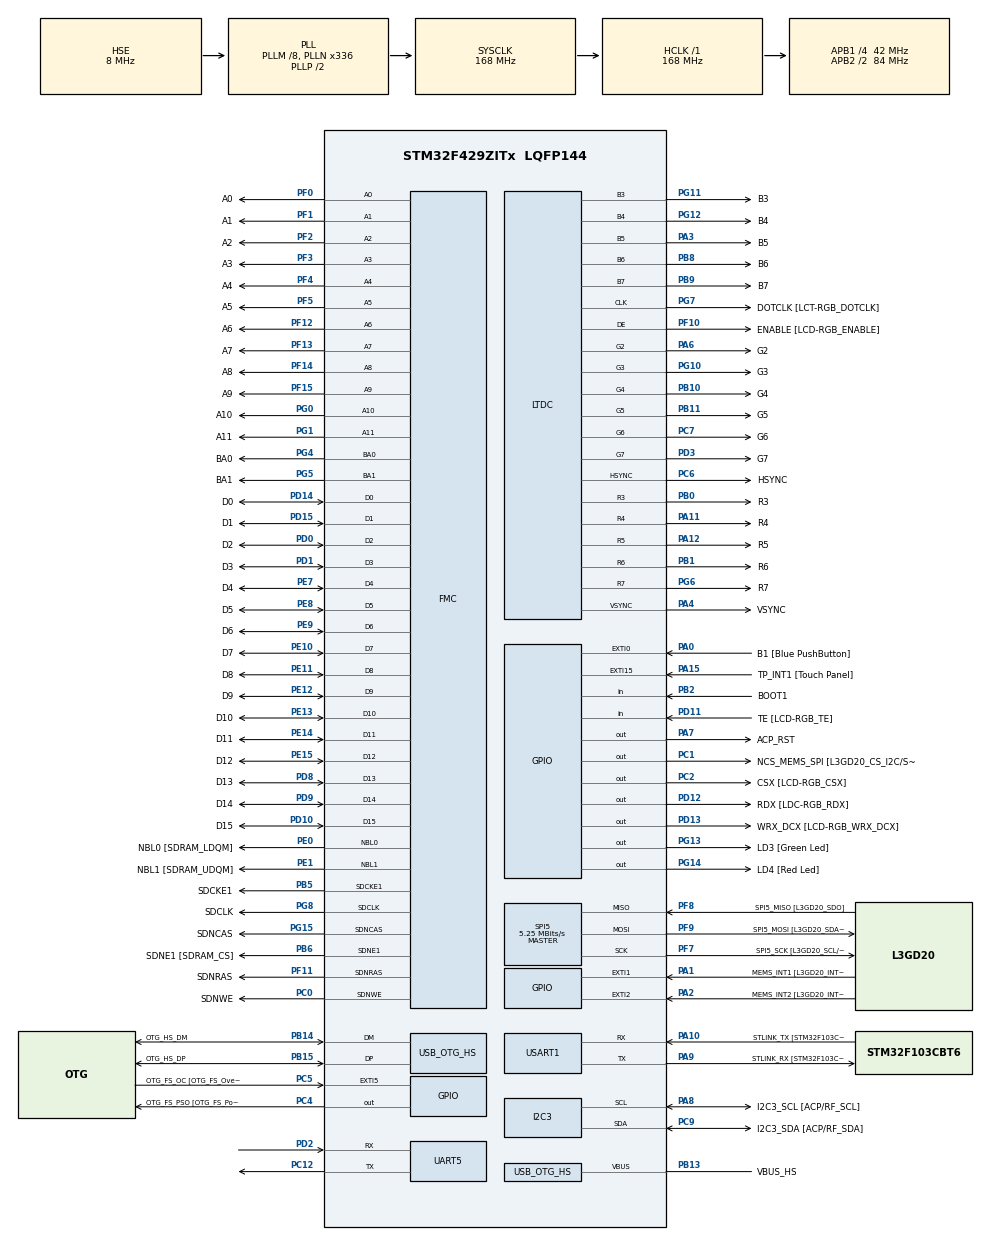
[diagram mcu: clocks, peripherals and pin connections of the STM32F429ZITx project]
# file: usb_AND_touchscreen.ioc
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FMC.CASLatency1=FMC_SDRAM_CAS_LATENCY_3
FMC.ExitSelfRefreshDelay1=7
FMC.LoadToActiveDelay1=2
FMC.RCDDelay1=2
FMC.RPDelay1=2
FMC.RPDelay2=2
FMC.ReadBurst1=FMC_SDRAM_RBURST_DISABLE
FMC.ReadPipeDelay1=FMC_SDRAM_RPIPE_DELAY_1
FMC.ReadPipeDelay2=FMC_SDRAM_RPIPE_DELAY_1
FMC.RowCycleDelay1=7
FMC.RowCycleDelay2=7
FMC.SDClockPeriod1=FMC_SDRAM_CLOCK_PERIOD_2
FMC.SDClockPeriod2=FMC_SDRAM_CLOCK_PERIOD_2
FMC.SelfRefreshTime1=4
FMC.WriteRecoveryTime1=3
LTDC.ActiveH=320
LTDC.ActiveW=240
LTDC.Alpha_L0=255
LTDC.BlendingFactor1_L0=LTDC_BLENDING_FACTOR1_PAxCA
LTDC.BlendingFactor2_L0=LTDC_BLENDING_FACTOR2_PAxCA
LTDC.FBStartAdress_L0=0xD0000000
LTDC.HBP=20
LTDC.HFP=10
LTDC.HSync=10
LTDC.ImageHeight_L0=320
LTDC.ImageWidth_L0=240
LTDC.Layers=0
LTDC.PixelFormat_L0=LTDC_PIXEL_FORMAT_RGB565
LTDC.VFP=4
LTDC.VSync=2
LTDC.WindowX1_L0=240
LTDC.WindowY1_L0=320
Mcu.Family=STM32F4
Mcu.Name=STM32F429ZITx
Mcu.Package=LQFP144
NVIC.DMA2D_IRQn=true\:5\:0\:true\:false\:true\:true\:true\:true
NVIC.LTDC_IRQn=true\:5\:0\:true\:false\:true\:true\:true\:true
NVIC.OTG_HS_IRQn=true\:0\:0\:false\:false\:true\:true\:true\:true
NVIC.PriorityGroup=NVIC_PRIORITYGROUP_4
NVIC.TIM1_UP_TIM10_IRQn=true\:0\:0\:false\:false\:true\:true\:true\:true
NVIC.TIM6_DAC_IRQn=true\:15\:0\:false\:false\:true\:false\:true\:true
NVIC.TimeBase=TIM6_DAC_IRQn
NVIC.TimeBaseIP=TIM6
PA0/WKUP.GPIO_Label=B1 [Blue PushButton]
PA0/WKUP.GPIO_ModeDefaultEXTI=GPIO_MODE_EVT_RISING
PA0/WKUP.GPIO_PuPd=GPIO_NOPULL
PA0/WKUP.Signal=GPXTI0
PA1.GPIO_Label=MEMS_INT1 [L3GD20_INT1]
PA1.GPIO_ModeDefaultEXTI=GPIO_MODE_EVT_RISING
PA1.GPIO_PuPd=GPIO_NOPULL
PA1.Signal=GPXTI1
PA10.GPIO_Label=STLINK_TX [STM32F103CBT6_PA2]
PA10.Mode=Asynchronous
PA10.Signal=USART1_RX
PA11.GPIO_Label=R4
PA11.GPIO_Mode=GPIO_MODE_AF_PP
PA11.GPIO_PuPd=GPIO_NOPULL
PA11.GPIO_Speed=GPIO_SPEED_FREQ_LOW
PA11.Mode=RGB565
PA11.Signal=LTDC_R4
PA12.GPIO_Label=R5
PA12.GPIO_Mode=GPIO_MODE_AF_PP
PA12.GPIO_PuPd=GPIO_NOPULL
PA12.GPIO_Speed=GPIO_SPEED_FREQ_LOW
PA12.Mode=RGB565
PA12.Signal=LTDC_R5
PA13.GPIO_Label=SWDIO
PA13.Mode=Serial_Wire
PA13.Signal=SYS_JTMS-SWDIO
PA14.GPIO_Label=SWCLK
PA14.Mode=Serial_Wire
PA14.Signal=SYS_JTCK-SWCLK
PA15.GPIO_Label=TP_INT1 [Touch Panel]
PA15.GPIO_ModeDefaultEXTI=GPIO_MODE_EVT_RISING
PA15.GPIO_PuPd=GPIO_NOPULL
PA15.Signal=GPXTI15
PA2.GPIO_Label=MEMS_INT2 [L3GD20_INT2]
PA2.GPIO_ModeDefaultEXTI=GPIO_MODE_EVT_RISING
PA2.GPIO_PuPd=GPIO_NOPULL
PA2.Signal=GPXTI2
PA3.GPIO_Label=B5
PA3.GPIO_Mode=GPIO_MODE_AF_PP
PA3.GPIO_PuPd=GPIO_NOPULL
PA3.GPIO_Speed=GPIO_SPEED_FREQ_LOW
PA3.Mode=RGB565
PA3.Signal=LTDC_B5
PA4.GPIO_Label=VSYNC
PA4.GPIO_Mode=GPIO_MODE_AF_PP
PA4.GPIO_PuPd=GPIO_NOPULL
PA4.GPIO_Speed=GPIO_SPEED_FREQ_LOW
PA4.Mode=RGB565
PA4.Signal=LTDC_VSYNC
PA6.GPIO_Label=G2
PA6.GPIO_Mode=GPIO_MODE_AF_PP
PA6.GPIO_PuPd=GPIO_NOPULL
PA6.GPIO_Speed=GPIO_SPEED_FREQ_LOW
PA6.Mode=RGB565
PA6.Signal=LTDC_G2
PA7.GPIO_Label=ACP_RST
PA7.GPIO_Mode=GPIO_MODE_OUTPUT_PP
PA7.GPIO_PuPd=GPIO_NOPULL
PA7.GPIO_Speed=GPIO_SPEED_FREQ_LOW
PA7.Signal=GPIO_Output
PA8.GPIO_Label=I2C3_SCL [ACP/RF_SCL]
PA8.GPIO_Mode=GPIO_MODE_AF_OD
PA8.GPIO_Pu=GPIO_PULLUP
PA8.GPIO_PuPd=GPIO_NOPULL
PA8.GPIO_Speed=GPIO_SPEED_FREQ_LOW
PA8.Mode=I2C
PA8.Signal=I2C3_SCL
PA9.GPIO_Label=STLINK_RX [STM32F103CBT6_PA3]
PA9.Mode=Asynchronous
PA9.Signal=USART1_TX
PB0.GPIO_Label=R3
PB0.GPIO_Mode=GPIO_MODE_AF_PP
PB0.GPIO_PuPd=GPIO_NOPULL
PB0.GPIO_Speed=GPIO_SPEED_FREQ_LOW
PB0.Mode=RGB565
PB0.Signal=LTDC_R3
PB1.GPIO_Label=R6
PB1.GPIO_Mode=GPIO_MODE_AF_PP
PB1.GPIO_PuPd=GPIO_NOPULL
PB1.GPIO_Speed=GPIO_SPEED_FREQ_LOW
PB1.Mode=RGB565
PB1.Signal=LTDC_R6
PB10.GPIO_Label=G4
PB10.GPIO_Mode=GPIO_MODE_AF_PP
PB10.GPIO_PuPd=GPIO_NOPULL
PB10.GPIO_Speed=GPIO_SPEED_FREQ_LOW
PB10.Mode=RGB565
PB10.Signal=LTDC_G4
PB11.GPIO_Label=G5
PB11.GPIO_Mode=GPIO_MODE_AF_PP
PB11.GPIO_PuPd=GPIO_NOPULL
PB11.GPIO_Speed=GPIO_SPEED_FREQ_LOW
PB11.Mode=RGB565
PB11.Signal=LTDC_G5
PB12.GPIO_Label=OTG_HS_ID
PB12.GPIO_Mode=GPIO_MODE_AF_PP
PB12.GPIO_PuPd=GPIO_NOPULL
PB12.GPIO_Speed=GPIO_SPEED_FREQ_LOW
PB12.Signal=USB_OTG_HS_ID
PB13.GPIO_Label=VBUS_HS
PB13.GPIO_Mode=GPIO_MODE_INPUT
PB13.GPIO_PuPd=GPIO_NOPULL
PB13.Mode=Activate_VBUS_FS
PB13.Signal=USB_OTG_HS_VBUS
PB14.GPIO_Label=OTG_HS_DM
PB14.GPIO_Mode=GPIO_MODE_AF_PP
PB14.GPIO_PuPd=GPIO_NOPULL
PB14.GPIO_Speed=GPIO_SPEED_FREQ_LOW
PB14.Mode=Host_FS
PB14.Signal=USB_OTG_HS_DM
PB15.GPIO_Label=OTG_HS_DP
PB15.GPIO_Mode=GPIO_MODE_AF_PP
PB15.GPIO_PuPd=GPIO_NOPULL
PB15.GPIO_Speed=GPIO_SPEED_FREQ_LOW
PB15.Mode=Host_FS
PB15.Signal=USB_OTG_HS_DP
PB2/BOOT1.GPIO_Label=BOOT1
PB2/BOOT1.GPIO_Mode=GPIO_MODE_INPUT
PB2/BOOT1.GPIO_PuPd=GPIO_NOPULL
PB2/BOOT1.Signal=GPIO_Input
PB5.GPIO_Label=SDCKE1
PB5.GPIO_Mode=GPIO_MODE_AF_PP
PB5.GPIO_PuPd=GPIO_NOPULL
PB5.GPIO_Speed=GPIO_SPEED_FREQ_VERY_HIGH
PB5.Mode=SdramChipSelect2_1
PB5.Signal=FMC_SDCKE1
PB6.GPIO_Label=SDNE1 [SDRAM_CS]
PB6.GPIO_Mode=GPIO_MODE_AF_PP
PB6.GPIO_PuPd=GPIO_NOPULL
PB6.GPIO_Speed=GPIO_SPEED_FREQ_VERY_HIGH
PB6.Mode=SdramChipSelect2_1
PB6.Signal=FMC_SDNE1
PB8.GPIO_Label=B6
PB8.GPIO_Mode=GPIO_MODE_AF_PP
PB8.GPIO_PuPd=GPIO_NOPULL
PB8.GPIO_Speed=GPIO_SPEED_FREQ_LOW
PB8.Mode=RGB565
PB8.Signal=LTDC_B6
PB9.GPIO_Label=B7
PB9.GPIO_Mode=GPIO_MODE_AF_PP
PB9.GPIO_PuPd=GPIO_NOPULL
PB9.GPIO_Speed=GPIO_SPEED_FREQ_LOW
PB9.Mode=RGB565
PB9.Signal=LTDC_B7
PC0.GPIO_Label=SDNWE
PC0.GPIO_Mode=GPIO_MODE_AF_PP
PC0.GPIO_PuPd=GPIO_NOPULL
PC0.GPIO_Speed=GPIO_SPEED_FREQ_VERY_HIGH
PC0.Signal=FMC_SDNWE
PC1.GPIO_Label=NCS_MEMS_SPI [L3GD20_CS_I2C/SPI]
PC1.GPIO_Mode=GPIO_MODE_OUTPUT_PP
PC1.GPIO_PuPd=GPIO_NOPULL
PC1.GPIO_Speed=GPIO_SPEED_FREQ_LOW
PC1.Signal=GPIO_Output
PC10.GPIO_Label=R2
PC10.GPIO_Mode=GPIO_MODE_AF_PP
PC10.GPIO_PuPd=GPIO_NOPULL
PC10.GPIO_Speed=GPIO_SPEED_FREQ_LOW
PC10.Signal=LTDC_R2
PC12.Mode=Asynchronous
PC12.Signal=UART5_TX
PC14/OSC32_IN.GPIO_Label=PC14-OSC32_IN
PC14/OSC32_IN.Signal=RCC_OSC32_IN
PC15/OSC32_OUT.GPIO_Label=PC15-OSC32_OUT
PC15/OSC32_OUT.Signal=RCC_OSC32_OUT
PC2.GPIO_Label=CSX [LCD-RGB_CSX]
PC2.GPIO_Mode=GPIO_MODE_OUTPUT_PP
PC2.GPIO_PuPd=GPIO_NOPULL
PC2.GPIO_Speed=GPIO_SPEED_FREQ_LOW
PC2.Signal=GPIO_Output
PC4.GPIO_Label=OTG_FS_PSO [OTG_FS_PowerSwitchOn]
PC4.GPIO_Mode=GPIO_MODE_OUTPUT_PP
PC4.GPIO_PuPd=GPIO_NOPULL
PC4.GPIO_Speed=GPIO_SPEED_FREQ_LOW
PC4.Signal=GPIO_Output
PC5.GPIO_Label=OTG_FS_OC [OTG_FS_OverCurrent]
PC5.GPIO_ModeDefaultEXTI=GPIO_MODE_EVT_RISING
PC5.Signal=GPXTI5
PC6.GPIO_Label=HSYNC
PC6.GPIO_Mode=GPIO_MODE_AF_PP
PC6.GPIO_PuPd=GPIO_NOPULL
PC6.GPIO_Speed=GPIO_SPEED_FREQ_LOW
PC6.Mode=RGB565
PC6.Signal=LTDC_HSYNC
PC7.GPIO_Label=G6
PC7.GPIO_Mode=GPIO_MODE_AF_PP
PC7.GPIO_PuPd=GPIO_NOPULL
PC7.GPIO_Speed=GPIO_SPEED_FREQ_LOW
PC7.Mode=RGB565
PC7.Signal=LTDC_G6
PC9.GPIO_Label=I2C3_SDA [ACP/RF_SDA]
PC9.GPIO_Mode=GPIO_MODE_AF_OD
PC9.GPIO_Pu=GPIO_PULLUP
PC9.GPIO_PuPd=GPIO_NOPULL
PC9.GPIO_Speed=GPIO_SPEED_FREQ_LOW
PC9.Mode=I2C
PC9.Signal=I2C3_SDA
PD0.GPIO_Label=D2
PD0.GPIO_Mode=GPIO_MODE_AF_PP
PD0.GPIO_PuPd=GPIO_NOPULL
PD0.GPIO_Speed=GPIO_SPEED_FREQ_VERY_HIGH
PD0.Signal=FMC_D2_DA2
PD1.GPIO_Label=D3
PD1.GPIO_Mode=GPIO_MODE_AF_PP
PD1.GPIO_PuPd=GPIO_NOPULL
PD1.GPIO_Speed=GPIO_SPEED_FREQ_VERY_HIGH
PD1.Signal=FMC_D3_DA3
PD10.GPIO_Label=D15
PD10.GPIO_Mode=GPIO_MODE_AF_PP
PD10.GPIO_PuPd=GPIO_NOPULL
PD10.GPIO_Speed=GPIO_SPEED_FREQ_VERY_HIGH
PD10.Signal=FMC_D15_DA15
PD11.GPIO_Label=TE [LCD-RGB_TE]
PD11.GPIO_Mode=GPIO_MODE_INPUT
PD11.GPIO_PuPd=GPIO_NOPULL
PD11.Signal=GPIO_Input
PD12.GPIO_Label=RDX [LDC-RGB_RDX]
PD12.GPIO_Mode=GPIO_MODE_OUTPUT_PP
PD12.GPIO_PuPd=GPIO_NOPULL
PD12.GPIO_Speed=GPIO_SPEED_FREQ_LOW
PD12.Signal=GPIO_Output
PD13.GPIO_Label=WRX_DCX [LCD-RGB_WRX_DCX]
PD13.GPIO_Mode=GPIO_MODE_OUTPUT_PP
PD13.GPIO_PuPd=GPIO_NOPULL
PD13.GPIO_Speed=GPIO_SPEED_FREQ_LOW
PD13.Signal=GPIO_Output
PD14.GPIO_Label=D0
PD14.GPIO_Mode=GPIO_MODE_AF_PP
PD14.GPIO_PuPd=GPIO_NOPULL
PD14.GPIO_Speed=GPIO_SPEED_FREQ_VERY_HIGH
PD14.Signal=FMC_D0_DA0
PD15.GPIO_Label=D1
PD15.GPIO_Mode=GPIO_MODE_AF_PP
PD15.GPIO_PuPd=GPIO_NOPULL
PD15.GPIO_Speed=GPIO_SPEED_FREQ_VERY_HIGH
PD15.Signal=FMC_D1_DA1
PD2.Mode=Asynchronous
PD2.Signal=UART5_RX
PD3.GPIO_Label=G7
PD3.GPIO_Mode=GPIO_MODE_AF_PP
PD3.GPIO_PuPd=GPIO_NOPULL
PD3.GPIO_Speed=GPIO_SPEED_FREQ_LOW
PD3.Mode=RGB565
PD3.Signal=LTDC_G7
PD5.Signal=USART2_TX
PD6.GPIO_Label=B2
PD6.GPIO_Mode=GPIO_MODE_AF_PP
PD6.GPIO_PuPd=GPIO_NOPULL
PD6.GPIO_Speed=GPIO_SPEED_FREQ_LOW
PD6.Signal=LTDC_B2
PD8.GPIO_Label=D13
PD8.GPIO_Mode=GPIO_MODE_AF_PP
PD8.GPIO_PuPd=GPIO_NOPULL
PD8.GPIO_Speed=GPIO_SPEED_FREQ_VERY_HIGH
PD8.Signal=FMC_D13_DA13
PD9.GPIO_Label=D14
PD9.GPIO_Mode=GPIO_MODE_AF_PP
PD9.GPIO_PuPd=GPIO_NOPULL
PD9.GPIO_Speed=GPIO_SPEED_FREQ_VERY_HIGH
PD9.Signal=FMC_D14_DA14
PE0.GPIO_Label=NBL0 [SDRAM_LDQM]
PE0.GPIO_Mode=GPIO_MODE_AF_PP
PE0.GPIO_PuPd=GPIO_NOPULL
PE0.GPIO_Speed=GPIO_SPEED_FREQ_VERY_HIGH
PE0.Signal=FMC_NBL0
PE1.GPIO_Label=NBL1 [SDRAM_UDQM]
PE1.GPIO_Mode=GPIO_MODE_AF_PP
PE1.GPIO_PuPd=GPIO_NOPULL
PE1.GPIO_Speed=GPIO_SPEED_FREQ_VERY_HIGH
PE1.Signal=FMC_NBL1
PE10.GPIO_Label=D7
PE10.GPIO_Mode=GPIO_MODE_AF_PP
PE10.GPIO_PuPd=GPIO_NOPULL
PE10.GPIO_Speed=GPIO_SPEED_FREQ_VERY_HIGH
PE10.Signal=FMC_D7_DA7
PE11.GPIO_Label=D8
PE11.GPIO_Mode=GPIO_MODE_AF_PP
PE11.GPIO_PuPd=GPIO_NOPULL
PE11.GPIO_Speed=GPIO_SPEED_FREQ_VERY_HIGH
PE11.Signal=FMC_D8_DA8
PE12.GPIO_Label=D9
PE12.GPIO_Mode=GPIO_MODE_AF_PP
PE12.GPIO_PuPd=GPIO_NOPULL
PE12.GPIO_Speed=GPIO_SPEED_FREQ_VERY_HIGH
PE12.Signal=FMC_D9_DA9
PE13.GPIO_Label=D10
PE13.GPIO_Mode=GPIO_MODE_AF_PP
PE13.GPIO_PuPd=GPIO_NOPULL
PE13.GPIO_Speed=GPIO_SPEED_FREQ_VERY_HIGH
PE13.Signal=FMC_D10_DA10
PE14.GPIO_Label=D11
PE14.GPIO_Mode=GPIO_MODE_AF_PP
PE14.GPIO_PuPd=GPIO_NOPULL
PE14.GPIO_Speed=GPIO_SPEED_FREQ_VERY_HIGH
PE14.Signal=FMC_D11_DA11
PE15.GPIO_Label=D12
PE15.GPIO_Mode=GPIO_MODE_AF_PP
PE15.GPIO_PuPd=GPIO_NOPULL
PE15.GPIO_Speed=GPIO_SPEED_FREQ_VERY_HIGH
PE15.Signal=FMC_D12_DA12
PE7.GPIO_Label=D4
PE7.GPIO_Mode=GPIO_MODE_AF_PP
PE7.GPIO_PuPd=GPIO_NOPULL
PE7.GPIO_Speed=GPIO_SPEED_FREQ_VERY_HIGH
PE7.Signal=FMC_D4_DA4
PE8.GPIO_Label=D5
PE8.GPIO_Mode=GPIO_MODE_AF_PP
PE8.GPIO_PuPd=GPIO_NOPULL
PE8.GPIO_Speed=GPIO_SPEED_FREQ_VERY_HIGH
PE8.Signal=FMC_D5_DA5
PE9.GPIO_Label=D6
PE9.GPIO_Mode=GPIO_MODE_AF_PP
PE9.GPIO_PuPd=GPIO_NOPULL
PE9.GPIO_Speed=GPIO_SPEED_FREQ_VERY_HIGH
PE9.Signal=FMC_D6_DA6
PF0.GPIO_Label=A0
PF0.GPIO_Mode=GPIO_MODE_AF_PP
PF0.GPIO_PuPd=GPIO_NOPULL
PF0.GPIO_Speed=GPIO_SPEED_FREQ_VERY_HIGH
PF0.Signal=FMC_A0
PF1.GPIO_Label=A1
PF1.GPIO_Mode=GPIO_MODE_AF_PP
PF1.GPIO_PuPd=GPIO_NOPULL
PF1.GPIO_Speed=GPIO_SPEED_FREQ_VERY_HIGH
PF1.Signal=FMC_A1
PF10.GPIO_Label=ENABLE [LCD-RGB_ENABLE]
PF10.GPIO_Mode=GPIO_MODE_AF_PP
PF10.GPIO_PuPd=GPIO_NOPULL
PF10.GPIO_Speed=GPIO_SPEED_FREQ_LOW
PF10.Mode=RGB565
PF10.Signal=LTDC_DE
PF11.GPIO_Label=SDNRAS
PF11.GPIO_Mode=GPIO_MODE_AF_PP
PF11.GPIO_PuPd=GPIO_NOPULL
PF11.GPIO_Speed=GPIO_SPEED_FREQ_VERY_HIGH
PF11.Signal=FMC_SDNRAS
PF12.GPIO_Label=A6
PF12.GPIO_Mode=GPIO_MODE_AF_PP
PF12.GPIO_PuPd=GPIO_NOPULL
PF12.GPIO_Speed=GPIO_SPEED_FREQ_VERY_HIGH
PF12.Signal=FMC_A6
PF13.GPIO_Label=A7
PF13.GPIO_Mode=GPIO_MODE_AF_PP
PF13.GPIO_PuPd=GPIO_NOPULL
PF13.GPIO_Speed=GPIO_SPEED_FREQ_VERY_HIGH
PF13.Signal=FMC_A7
PF14.GPIO_Label=A8
PF14.GPIO_Mode=GPIO_MODE_AF_PP
PF14.GPIO_PuPd=GPIO_NOPULL
PF14.GPIO_Speed=GPIO_SPEED_FREQ_VERY_HIGH
PF14.Signal=FMC_A8
PF15.GPIO_Label=A9
PF15.GPIO_Mode=GPIO_MODE_AF_PP
PF15.GPIO_PuPd=GPIO_NOPULL
PF15.GPIO_Speed=GPIO_SPEED_FREQ_VERY_HIGH
PF15.Signal=FMC_A9
PF2.GPIO_Label=A2
PF2.GPIO_Mode=GPIO_MODE_AF_PP
PF2.GPIO_PuPd=GPIO_NOPULL
PF2.GPIO_Speed=GPIO_SPEED_FREQ_VERY_HIGH
PF2.Signal=FMC_A2
PF3.GPIO_Label=A3
PF3.GPIO_Mode=GPIO_MODE_AF_PP
PF3.GPIO_PuPd=GPIO_NOPULL
PF3.GPIO_Speed=GPIO_SPEED_FREQ_VERY_HIGH
PF3.Signal=FMC_A3
PF4.GPIO_Label=A4
PF4.GPIO_Mode=GPIO_MODE_AF_PP
PF4.GPIO_PuPd=GPIO_NOPULL
PF4.GPIO_Speed=GPIO_SPEED_FREQ_VERY_HIGH
PF4.Signal=FMC_A4
PF5.GPIO_Label=A5
PF5.GPIO_Mode=GPIO_MODE_AF_PP
PF5.GPIO_PuPd=GPIO_NOPULL
PF5.GPIO_Speed=GPIO_SPEED_FREQ_VERY_HIGH
PF5.Signal=FMC_A5
PF7.GPIO_Label=SPI5_SCK [L3GD20_SCL/SPC]
PF7.GPIO_Mode=GPIO_MODE_AF_PP
PF7.GPIO_PuPd=GPIO_NOPULL
PF7.GPIO_Speed=GPIO_SPEED_FREQ_LOW
PF7.Mode=Full_Duplex_Master
PF7.Signal=SPI5_SCK
PF8.GPIO_Label=SPI5_MISO [L3GD20_SDO]
PF8.GPIO_Mode=GPIO_MODE_AF_PP
PF8.GPIO_PuPd=GPIO_NOPULL
PF8.GPIO_Speed=GPIO_SPEED_FREQ_LOW
PF8.Mode=Full_Duplex_Master
PF8.Signal=SPI5_MISO
PF9.GPIO_Label=SPI5_MOSI [L3GD20_SDA/SDI/SDO]
PF9.GPIO_Mode=GPIO_MODE_AF_PP
PF9.GPIO_PuPd=GPIO_NOPULL
PF9.GPIO_Speed=GPIO_SPEED_FREQ_LOW
PF9.Mode=Full_Duplex_Master
PF9.Signal=SPI5_MOSI
PG0.GPIO_Label=A10
PG0.GPIO_Mode=GPIO_MODE_AF_PP
PG0.GPIO_PuPd=GPIO_NOPULL
PG0.GPIO_Speed=GPIO_SPEED_FREQ_VERY_HIGH
PG0.Signal=FMC_A10
PG1.GPIO_Label=A11
PG1.GPIO_Mode=GPIO_MODE_AF_PP
PG1.GPIO_PuPd=GPIO_NOPULL
PG1.GPIO_Speed=GPIO_SPEED_FREQ_VERY_HIGH
PG1.Signal=FMC_A11
PG10.GPIO_Label=G3
PG10.GPIO_Mode=GPIO_MODE_AF_PP
PG10.GPIO_PuPd=GPIO_NOPULL
PG10.GPIO_Speed=GPIO_SPEED_FREQ_LOW
PG10.Mode=RGB565
PG10.Signal=LTDC_G3
PG11.GPIO_Label=B3
PG11.GPIO_Mode=GPIO_MODE_AF_PP
PG11.GPIO_PuPd=GPIO_NOPULL
PG11.GPIO_Speed=GPIO_SPEED_FREQ_LOW
PG11.Mode=RGB565
PG11.Signal=LTDC_B3
PG12.GPIO_Label=B4
PG12.GPIO_Mode=GPIO_MODE_AF_PP
PG12.GPIO_PuPd=GPIO_NOPULL
PG12.GPIO_Speed=GPIO_SPEED_FREQ_LOW
PG12.Mode=RGB565
PG12.Signal=LTDC_B4
PG13.GPIO_Label=LD3 [Green Led]
PG13.GPIO_Mode=GPIO_MODE_OUTPUT_PP
PG13.GPIO_PuPd=GPIO_NOPULL
PG13.GPIO_Speed=GPIO_SPEED_FREQ_LOW
PG13.Signal=GPIO_Output
PG14.GPIO_Label=LD4 [Red Led]
PG14.GPIO_Mode=GPIO_MODE_OUTPUT_PP
PG14.GPIO_PuPd=GPIO_NOPULL
PG14.GPIO_Speed=GPIO_SPEED_FREQ_LOW
PG14.Signal=GPIO_Output
PG15.GPIO_Label=SDNCAS
PG15.GPIO_Mode=GPIO_MODE_AF_PP
PG15.GPIO_PuPd=GPIO_NOPULL
PG15.GPIO_Speed=GPIO_SPEED_FREQ_VERY_HIGH
PG15.Signal=FMC_SDNCAS
PG4.GPIO_Label=BA0
PG4.GPIO_Mode=GPIO_MODE_AF_PP
PG4.GPIO_PuPd=GPIO_NOPULL
PG4.GPIO_Speed=GPIO_SPEED_FREQ_VERY_HIGH
PG4.Signal=FMC_A14_BA0
PG5.GPIO_Label=BA1
PG5.GPIO_Mode=GPIO_MODE_AF_PP
PG5.GPIO_PuPd=GPIO_NOPULL
PG5.GPIO_Speed=GPIO_SPEED_FREQ_VERY_HIGH
PG5.Signal=FMC_A15_BA1
PG6.GPIO_Label=R7
PG6.GPIO_Mode=GPIO_MODE_AF_PP
PG6.GPIO_PuPd=GPIO_NOPULL
PG6.GPIO_Speed=GPIO_SPEED_FREQ_LOW
PG6.Mode=RGB565
PG6.Signal=LTDC_R7
PG7.GPIO_Label=DOTCLK [LCT-RGB_DOTCLK]
PG7.GPIO_Mode=GPIO_MODE_AF_PP
PG7.GPIO_PuPd=GPIO_NOPULL
PG7.GPIO_Speed=GPIO_SPEED_FREQ_LOW
PG7.Mode=RGB565
PG7.Signal=LTDC_CLK
PG8.GPIO_Label=SDCLK
PG8.GPIO_Mode=GPIO_MODE_AF_PP
PG8.GPIO_PuPd=GPIO_NOPULL
PG8.GPIO_Speed=GPIO_SPEED_FREQ_VERY_HIGH
PG8.Signal=FMC_SDCLK
PH0/OSC_IN.GPIO_Label=PH0-OSC_IN
PH0/OSC_IN.Mode=HSE-External-Oscillator
PH0/OSC_IN.Signal=RCC_OSC_IN
PH1/OSC_OUT.GPIO_Label=PH1-OSC_OUT
PH1/OSC_OUT.Mode=HSE-External-Oscillator
PH1/OSC_OUT.Signal=RCC_OSC_OUT
ProjectManager.HeapSize=0x200
ProjectManager.StackSize=0x400
ProjectManager.TargetToolchain=STM32CubeIDE
RCC.48MHZClocksFreq_Value=48000000
RCC.AHBFreq_Value=168000000
RCC.APB1CLKDivider=RCC_HCLK_DIV4
RCC.APB1Freq_Value=42000000
RCC.APB1TimFreq_Value=84000000
RCC.APB2CLKDivider=RCC_HCLK_DIV2
RCC.APB2Freq_Value=84000000
RCC.APB2TimFreq_Value=168000000
RCC.CortexFreq_Value=168000000
RCC.FLatency-AdvancedSettings=FLASH_LATENCY_5
RCC.HCLKFreq_Value=168000000
RCC.HSE_VALUE=8000000
RCC.HSI_VALUE=16000000
RCC.LSE_VALUE=32768
RCC.PLLM=8
RCC.PLLN=336
RCC.PLLQ=7
RCC.PLLSAIDivR=RCC_PLLSAIDIVR_8
RCC.PLLSAIN=192
RCC.PLLSAIR=4
RCC.SYSCLKFreq_VALUE=168000000
RCC.SYSCLKSource=RCC_SYSCLKSOURCE_PLLCLK
RCC.VCOOutputFreq_Value=336000000
SH.FMC_A0.0=FMC_A0,12b-sda1
SH.FMC_A1.0=FMC_A1,12b-sda1
SH.FMC_A10.0=FMC_A10,12b-sda1
SH.FMC_A11.0=FMC_A11,12b-sda1
SH.FMC_A14_BA0.0=FMC_BA0,FourSdramBanks1
SH.FMC_A15_BA1.0=FMC_BA1,FourSdramBanks1
SH.FMC_A2.0=FMC_A2,12b-sda1
SH.FMC_A3.0=FMC_A3,12b-sda1
SH.FMC_A4.0=FMC_A4,12b-sda1
SH.FMC_A5.0=FMC_A5,12b-sda1
SH.FMC_A6.0=FMC_A6,12b-sda1
SH.FMC_A7.0=FMC_A7,12b-sda1
SH.FMC_A8.0=FMC_A8,12b-sda1
SH.FMC_A9.0=FMC_A9,12b-sda1
SH.FMC_D0_DA0.0=FMC_D0,sd-16b-d1
SH.FMC_D10_DA10.0=FMC_D10,sd-16b-d1
SH.FMC_D11_DA11.0=FMC_D11,sd-16b-d1
SH.FMC_D12_DA12.0=FMC_D12,sd-16b-d1
SH.FMC_D13_DA13.0=FMC_D13,sd-16b-d1
SH.FMC_D14_DA14.0=FMC_D14,sd-16b-d1
SH.FMC_D15_DA15.0=FMC_D15,sd-16b-d1
SH.FMC_D1_DA1.0=FMC_D1,sd-16b-d1
SH.FMC_D2_DA2.0=FMC_D2,sd-16b-d1
SH.FMC_D3_DA3.0=FMC_D3,sd-16b-d1
SH.FMC_D4_DA4.0=FMC_D4,sd-16b-d1
SH.FMC_D5_DA5.0=FMC_D5,sd-16b-d1
SH.FMC_D6_DA6.0=FMC_D6,sd-16b-d1
SH.FMC_D7_DA7.0=FMC_D7,sd-16b-d1
SH.FMC_D8_DA8.0=FMC_D8,sd-16b-d1
SH.FMC_D9_DA9.0=FMC_D9,sd-16b-d1
SH.FMC_NBL0.0=FMC_NBL0,Sd2ByteEnable1
SH.FMC_NBL1.0=FMC_NBL1,Sd2ByteEnable1
SH.FMC_SDCLK.0=FMC_SDCLK,12b-sda1
SH.FMC_SDNCAS.0=FMC_SDNCAS,12b-sda1
SH.FMC_SDNRAS.0=FMC_SDNRAS,12b-sda1
SH.FMC_SDNWE.0=FMC_SDNWE,12b-sda1
SPI5.BaudRatePrescaler=SPI_BAUDRATEPRESCALER_16
SPI5.CalculateBaudRate=5.25 MBits/s
SPI5.Direction=SPI_DIRECTION_2LINES
SPI5.Mode=SPI_MODE_MASTER
SPI5.VirtualType=VM_MASTER
TIM1.Prescaler=167
TIM10.AutoReloadPreload=TIM_AUTORELOAD_PRELOAD_ENABLE
TIM10.Period=10000
TIM10.Prescaler=1680-1
UART5.VirtualMode=Asynchronous
USART1.VirtualMode=VM_ASYNC
USB_HOST.BSP.number=1
USB_HOST.USBH_DEBUG_LEVEL-HID_HS=3
USB_HOST.USBH_HandleTypeDef-HID_HS=hUsbHostHS
USB_HOST.USBH_MAX_DATA_BUFFER-HID_HS=3000
USB_HOST.VirtualModeHS=Hid
USB_HOST0.BSP.STBoard=false
USB_HOST0.BSP.api=UnknownBspDriver
USB_HOST0.BSP.instance=PC4
USB_HOST0.BSP.ip=GPIO
USB_HOST0.BSP.mode=Output
USB_HOST0.BSP.name=Drive_VBUS_HS
USB_HOST0.BSP.solution=PC4
USB_OTG_HS.VirtualMode-Host_FS=Host_FS
VP_CRC_VS_CRC.Mode=CRC_Activate
VP_DMA2D_VS_DMA2D.Mode=DMA2D_Activate
VP_SYS_VS_tim6.Mode=TIM6
VP_TIM10_VS_ClockSourceINT.Mode=Enable_Timer
VP_TIM1_VS_ClockSourceINT.Mode=Internal
VP_USB_HOST_VS_USB_HOST_HID_HS.Mode=HID_HS
board=STM32F429I-DISC1

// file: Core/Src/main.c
/* USER CODE BEGIN Header */
/**
 ******************************************************************************
 * @file           : main.c
 * @brief          : Main program body
 ******************************************************************************
 * @attention
 *
 * Copyright (c) 2025 STMicroelectronics.
 * All rights reserved.
 *
 * This software is licensed under terms that can be found in the LICENSE file
 * in the root directory of this software component.
 * If no LICENSE file comes with this software, it is provided AS-IS.
 *
 ******************************************************************************
 */

/****** THIS IS THE PROGRAM FLOW SO YOU DON'T GET C *********/
/* Library includes
 * Definitions of macros
 * Setting up touchscreen variables
 * stm32 prewritten function definitions
 * private function definitions
 * QR scanner USB HID host user call back function event handling
 * Main initialization code: storing test protocols for debugging
 * Initialize hardware
 * Main loop calls the touch handler with interrupt and USB is handled by STM32
 * stm32 prewritten function implementations
 * flash memory functions come first
 * touchscreen functions after
 * lastly, interrupt handler
 */

/* USER CODE END Header */
#include "main.h"
#include "usb_host.h"

/* USER CODE BEGIN Includes */
#include "usbh_hid.h"
#include <string.h>
#include "stm32f429i_discovery_lcd.h"
#include "stm32f429i_discovery_ts.h"
/* USER CODE END Includes */

/* USER CODE BEGIN PD */
#define NULL_CHAR 0
#define SOH 1
#define NEWLINE_CHAR 10   //the '/r' in python is detected as a newline (10).
#define CARRIAGE_CHAR 13  //the '\n' is just ignored
#define TAB 9
#define TRASH 0xFF

/******** Flash Memory ********/
#define SECTOR_5      ((uint32_t)0x08020000) /* Base @ of Sector 5, 128 Kbytes */
#define SECTOR_6      ((uint32_t)0x08040000) /* Base @ of Sector 6, 128 Kbytes */
#define SECTOR_7      ((uint32_t)0x08060000) /* Base @ of Sector 7, 128 Kbytes */
#define SECTOR_8      ((uint32_t)0x08080000) /* Base @ of Sector 8, 128 Kbytes */
#define SECTOR_9      ((uint32_t)0x080A0000) /* Base @ of Sector 9, 128 Kbytes */
#define SECTOR_10     ((uint32_t)0x080C0000) /* Base @ of Sector 10, 128 Kbytes */
#define SECTOR_11     ((uint32_t)0x080E0000) /* Base @ of Sector 11, 128 Kbytes */
#define SECTOR_17     ((uint32_t)0x08120000) /* Base @ of Sector 5, 128 Kbytes */
#define SECTOR_18     ((uint32_t)0x08140000) /* Base @ of Sector 6, 128 Kbytes */
#define SECTOR_19     ((uint32_t)0x08160000) /* Base @ of Sector 7, 128 Kbytes */
#define SECTOR_20     ((uint32_t)0x08180000) /* Base @ of Sector 8, 128 Kbytes  */
#define SECTOR_21     ((uint32_t)0x081A0000) /* Base @ of Sector 9, 128 Kbytes  */
#define SECTOR_22     ((uint32_t)0x081C0000) /* Base @ of Sector 10, 128 Kbytes */
#define SECTOR_23     ((uint32_t)0x081E0000) /* Base @ of Sector 11, 128 Kbytes */

// Address where you want to store your data in flash
#define NUMBER_OF_SECTORS 14
#define MAX_PROTOCOLS_IN_SECTOR 3
#define PROTOCOL_SIZE 3000
#define MAX_LINES 100
#define MAX_LINE_LENGTH 32 //for linear movement it wont be more than 32 chars
#define MAX_TITLE_SIZE 12  //you can 10 chars, but also we need newline and null

/******** LCD DISPLAY ********/
#define BUTTON_WIDTH 160
#define BUTTON_HEIGHT 40
#define NUM_BUTTONS 3
#define Y_OFFSET 20
#define SCREEN_DELAY 50
#define MAX_QUEUE_SIZE 10

/* USER CODE END PD */

CRC_HandleTypeDef hcrc;

DMA2D_HandleTypeDef hdma2d;

I2C_HandleTypeDef hi2c3;

LTDC_HandleTypeDef hltdc;

SPI_HandleTypeDef hspi5;

TIM_HandleTypeDef htim1;
TIM_HandleTypeDef htim10;

UART_HandleTypeDef huart5;
UART_HandleTypeDef huart1;

SDRAM_HandleTypeDef hsdram1;

/* USER CODE BEGIN PV */
TS_StateTypeDef TS_State;           //store touchscreen state info here
static int count = 0;               //count for interrupt
static uint8_t checkTouchFlag = 0;  //interrupt flag for main loop

typedef enum {
	PAGE_MAIN, PAGE_SELECT, PAGE_QUEUE, PAGE_CONFIRMATION, PAGE_FINISH
} PageState;
PageState currentPage = PAGE_MAIN;

typedef enum {
	EMPTY = 0, NOT_EMPTY = 1
} ButtonStatus;

typedef struct {
	uint16_t x, y, w, h;
	char label[MAX_LINE_LENGTH];
	ButtonStatus status;
} Button;

Button buttons[NUM_BUTTONS] = { { 40, 50, BUTTON_WIDTH, BUTTON_HEIGHT,
		"Protocol 1", EMPTY }, { 40, 110, BUTTON_WIDTH, BUTTON_HEIGHT,
		"Protocol 2", EMPTY }, { 40, 170, BUTTON_WIDTH, BUTTON_HEIGHT,
		"Protocol 3", EMPTY } };

Button queueButton = { 10, 270, 80, 30, "Queue" }; //x, y, w, h, label
Button backButton = { 10, 270, 80, 30, "Back" }; //x, y, w, h, label
Button nextButton = { 150, 270, 80, 30, "Next" };
Button runButton = { 150, 270, 80, 30, "Run" };
Button confirmButton = { 70, 160, 120, 40, "Confirm" };
Button queueSelectButton = { 70, 60, 100, 40, "Queue" }; //x, y, w, h, label
Button selectButton = { 70, 120, 100, 40, "Run" };
Button deleteButton = { 70, 180, 100, 40, "Delete" };

/* USER CODE END PV */

void SystemClock_Config(void);
static void MX_GPIO_Init(void);
static void MX_CRC_Init(void);
static void MX_DMA2D_Init(void);
static void MX_FMC_Init(void);
static void MX_I2C3_Init(void);
static void MX_LTDC_Init(void);
static void MX_SPI5_Init(void);
static void MX_TIM1_Init(void);
static void MX_USART1_UART_Init(void);
static void MX_TIM10_Init(void);
static void MX_UART5_Init(void);
void MX_USB_HOST_Process(void);

/* USER CODE BEGIN PFP */
void output_protocol(char line[MAX_LINES][MAX_LINE_LENGTH], int lines);

/****TOUCHSCREEN PRIVATE FUNCTIONS*******/
void erase_sector(uint32_t Sector);
void write_to_flash(const char *data, uint32_t flash_address);
uint8_t read_from_flash(char *output, uint32_t flash_address);
uint8_t storeProtocol(char gcode_file[MAX_LINES][MAX_LINE_LENGTH],
		uint32_t sector);
uint32_t sector_mapping(uint32_t sector);
uint8_t get_num_protocols_in_sector(uint32_t sector);
uint8_t get_num_lines_in_protocol(char protocol[MAX_LINES][MAX_LINE_LENGTH]);
uint8_t getFreeSector(void);
void transmitProtocol(uint32_t sector, uint32_t offset);
void queueProtocol(uint32_t sector, uint32_t offset);
void transmitQueuedProtocols(uint8_t queueSize);
uint32_t get_sector_address(uint32_t sector);
void write_number_to_flash(uint32_t flash_address, uint32_t number);
void DrawQueuePage(uint8_t queueSize);
void Touch_Init(void);
uint8_t HandleTouch(void);
void DrawMainPage(uint8_t page_num);
void DrawInfoPage(char protocolTitle[MAX_LINE_LENGTH]);
void DrawConfirmationPage(uint32_t sector, uint32_t offset);

/* USER CODE END PFP */

/* USER CODE BEGIN 0 */
/********** QR SCANNER HANDLED THROUGH USB CALL BACK FUNCTION *********/
int i = 0;
int j = 0;
static char queueBuffer[MAX_QUEUE_SIZE][MAX_LINES][MAX_LINE_LENGTH];
static uint8_t queueSize = 0;
static uint8_t pageNum = 1;
static uint8_t USB_BUSY = 0;
char qr_code_data[MAX_LINES][MAX_LINE_LENGTH] = { { '\0' } }; //static initializes strings with all null characters
HID_KEYBD_Info_TypeDef *Keyboard_Info;

/***DORJEE YOU HAVE TO CHANGE USBH_HID.H WHEN YOU GENERATE CODE****/
void USBH_HID_EventCallback(USBH_HandleTypeDef *phost) { //2.6s for 54 lines
	Keyboard_Info = USBH_HID_GetKeybdInfo(phost);
	char key = USBH_HID_GetASCIICode(Keyboard_Info);
	//disable the touchscreen interrupt functionality when usb transmission starts
	//after tab it calls itself one more time, so disable after i=0
	if (i == 1) {
		USB_BUSY = 1;
	}

	//store incoming chars. ignore null characters that come in for some reason
	if ((key != NULL_CHAR) && (key != SOH)) {
		qr_code_data[i][j] = key;
		j++;
	}
	//handle new line
	if (key == NEWLINE_CHAR) {
		j = 0;
		i++;
	}
	//tab is the end of the qr code
	if (key == TAB) {
		for (int a = 0; a < 15; a++) {
			//printf("%s", qr_code_data[a]);
		}
		__disable_irq();
		//output_protocol(qr_code_data, i + 1);
		//check if the title is (10 chars + newline char) or less
		if (strlen(qr_code_data[0]) < (MAX_TITLE_SIZE + 1)) {
			uint8_t freeSectorNumber = getFreeSector();
			//printf("free sector is %d\n", freeSectorNumber);
			//only store the protocol if all memory isnt full
			if (freeSectorNumber <= 10) { //i only got 10 pages rn
				//printf("why\n");
				storeProtocol(qr_code_data, freeSectorNumber);
				//go to the page num the new protocol is on
				pageNum = freeSectorNumber;
				DrawMainPage(pageNum);
				currentPage = PAGE_MAIN;
				for (int a = 0; a < MAX_LINES; a++) {
					for (int b = 0; b < MAX_LINE_LENGTH; b++) {
						qr_code_data[a][b] = '\0';
					}
				}

			}
			__enable_irq();
			USB_BUSY = 0;
		}
		i = 0;
		j = 0;
	}

}
/* USER CODE END 0 */

int main(void) {

	/* MCU Configuration--------------------------------------------------------*/

	/* Reset of all peripherals, Initializes the Flash interface and the Systick. */
	HAL_Init();

	/* Configure the system clock */
	SystemClock_Config();

	/* Initialize all configured peripherals */
	MX_GPIO_Init();
	MX_CRC_Init();
	MX_DMA2D_Init();
	MX_FMC_Init();
	MX_I2C3_Init();
	MX_LTDC_Init();
	MX_SPI5_Init();
	MX_TIM1_Init();
	MX_USART1_UART_Init();
	MX_USB_HOST_Init();
	MX_TIM10_Init();
	MX_UART5_Init();
	/* USER CODE BEGIN 2 */
	printf("USB and Touchscreen Test\n");

	/****** manually erase sectors ****/
//	erase_sector(1);
//	erase_sector(2);
//	erase_sector(3);
//	erase_sector(4);
//	erase_sector(5);
//	erase_sector(6);
//	erase_sector(7);
//	erase_sector(8);
//	erase_sector(9);
//	erase_sector(10);
	printf("Sectors may have been erased\n");

	/******* TOUCHSCREEN INIT**********/
	BSP_LCD_Init();
	BSP_LCD_LayerDefaultInit(0, LCD_FRAME_BUFFER);
	BSP_LCD_Clear(LCD_COLOR_WHITE);
	Touch_Init();

	/******** START PROGRAM ************/
	DrawMainPage(1);
	HAL_TIM_Base_Start_IT(&htim10);   //start Interrupt Timer

	/* USER CODE END 2 */

	/* Infinite loop */
	while (1) {
		MX_USB_HOST_Process();

		/* USER CODE BEGIN 3 */

		if (checkTouchFlag) {
			HandleTouch();
			checkTouchFlag = 0;
		}
	}
	/* USER CODE END 3 */
}

void SystemClock_Config(void) {
	RCC_OscInitTypeDef RCC_OscInitStruct = { 0 };
	RCC_ClkInitTypeDef RCC_ClkInitStruct = { 0 };

	/** Configure the main internal regulator output voltage
	 */
	__HAL_RCC_PWR_CLK_ENABLE();
	__HAL_PWR_VOLTAGESCALING_CONFIG(PWR_REGULATOR_VOLTAGE_SCALE1);

	/** Initializes the RCC Oscillators according to the specified parameters
	 * in the RCC_OscInitTypeDef structure.
	 */
	RCC_OscInitStruct.OscillatorType = RCC_OSCILLATORTYPE_HSE;
	RCC_OscInitStruct.HSEState = RCC_HSE_ON;
	RCC_OscInitStruct.PLL.PLLState = RCC_PLL_ON;
	RCC_OscInitStruct.PLL.PLLSource = RCC_PLLSOURCE_HSE;
	RCC_OscInitStruct.PLL.PLLM = 8;
	RCC_OscInitStruct.PLL.PLLN = 336;
	RCC_OscInitStruct.PLL.PLLP = RCC_PLLP_DIV2;
	RCC_OscInitStruct.PLL.PLLQ = 7;
	if (HAL_RCC_OscConfig(&RCC_OscInitStruct) != HAL_OK) {
		Error_Handler();
	}

	/** Initializes the CPU, AHB and APB buses clocks
	 */
	RCC_ClkInitStruct.ClockType = RCC_CLOCKTYPE_HCLK | RCC_CLOCKTYPE_SYSCLK
			| RCC_CLOCKTYPE_PCLK1 | RCC_CLOCKTYPE_PCLK2;
	RCC_ClkInitStruct.SYSCLKSource = RCC_SYSCLKSOURCE_PLLCLK;
	RCC_ClkInitStruct.AHBCLKDivider = RCC_SYSCLK_DIV1;
	RCC_ClkInitStruct.APB1CLKDivider = RCC_HCLK_DIV4;
	RCC_ClkInitStruct.APB2CLKDivider = RCC_HCLK_DIV2;

	if (HAL_RCC_ClockConfig(&RCC_ClkInitStruct, FLASH_LATENCY_5) != HAL_OK) {
		Error_Handler();
	}
}

static void MX_CRC_Init(void) {

	hcrc.Instance = CRC;
	if (HAL_CRC_Init(&hcrc) != HAL_OK) {
		Error_Handler();
	}

}

static void MX_DMA2D_Init(void) {

	hdma2d.Instance = DMA2D;
	hdma2d.Init.Mode = DMA2D_M2M;
	hdma2d.Init.ColorMode = DMA2D_OUTPUT_ARGB8888;
	hdma2d.Init.OutputOffset = 0;
	hdma2d.LayerCfg[1].InputOffset = 0;
	hdma2d.LayerCfg[1].InputColorMode = DMA2D_INPUT_ARGB8888;
	hdma2d.LayerCfg[1].AlphaMode = DMA2D_NO_MODIF_ALPHA;
	hdma2d.LayerCfg[1].InputAlpha = 0;
	if (HAL_DMA2D_Init(&hdma2d) != HAL_OK) {
		Error_Handler();
	}
	if (HAL_DMA2D_ConfigLayer(&hdma2d, 1) != HAL_OK) {
		Error_Handler();
	}

}

static void MX_I2C3_Init(void) {

	hi2c3.Instance = I2C3;
	hi2c3.Init.ClockSpeed = 100000;
	hi2c3.Init.DutyCycle = I2C_DUTYCYCLE_2;
	hi2c3.Init.OwnAddress1 = 0;
	hi2c3.Init.AddressingMode = I2C_ADDRESSINGMODE_7BIT;
	hi2c3.Init.DualAddressMode = I2C_DUALADDRESS_DISABLE;
	hi2c3.Init.OwnAddress2 = 0;
	hi2c3.Init.GeneralCallMode = I2C_GENERALCALL_DISABLE;
	hi2c3.Init.NoStretchMode = I2C_NOSTRETCH_DISABLE;
	if (HAL_I2C_Init(&hi2c3) != HAL_OK) {
		Error_Handler();
	}

	/** Configure Analogue filter
	 */
	if (HAL_I2CEx_ConfigAnalogFilter(&hi2c3, I2C_ANALOGFILTER_ENABLE)
			!= HAL_OK) {
		Error_Handler();
	}

	/** Configure Digital filter
	 */
	if (HAL_I2CEx_ConfigDigitalFilter(&hi2c3, 0) != HAL_OK) {
		Error_Handler();
	}

}

static void MX_LTDC_Init(void) {

	LTDC_LayerCfgTypeDef pLayerCfg = { 0 };

	hltdc.Instance = LTDC;
	hltdc.Init.HSPolarity = LTDC_HSPOLARITY_AL;
	hltdc.Init.VSPolarity = LTDC_VSPOLARITY_AL;
	hltdc.Init.DEPolarity = LTDC_DEPOLARITY_AL;
	hltdc.Init.PCPolarity = LTDC_PCPOLARITY_IPC;
	hltdc.Init.HorizontalSync = 9;
	hltdc.Init.VerticalSync = 1;
	hltdc.Init.AccumulatedHBP = 29;
	hltdc.Init.AccumulatedVBP = 3;
	hltdc.Init.AccumulatedActiveW = 269;
	hltdc.Init.AccumulatedActiveH = 323;
	hltdc.Init.TotalWidth = 279;
	hltdc.Init.TotalHeigh = 327;
	hltdc.Init.Backcolor.Blue = 0;
	hltdc.Init.Backcolor.Green = 0;
	hltdc.Init.Backcolor.Red = 0;
	if (HAL_LTDC_Init(&hltdc) != HAL_OK) {
		Error_Handler();
	}
	pLayerCfg.WindowX0 = 0;
	pLayerCfg.WindowX1 = 240;
	pLayerCfg.WindowY0 = 0;
	pLayerCfg.WindowY1 = 320;
	pLayerCfg.PixelFormat = LTDC_PIXEL_FORMAT_RGB565;
	pLayerCfg.Alpha = 255;
	pLayerCfg.Alpha0 = 0;
	pLayerCfg.BlendingFactor1 = LTDC_BLENDING_FACTOR1_PAxCA;
	pLayerCfg.BlendingFactor2 = LTDC_BLENDING_FACTOR2_PAxCA;
	pLayerCfg.FBStartAdress = 0xD0000000;
	pLayerCfg.ImageWidth = 240;
	pLayerCfg.ImageHeight = 320;
	pLayerCfg.Backcolor.Blue = 0;
	pLayerCfg.Backcolor.Green = 0;
	pLayerCfg.Backcolor.Red = 0;
	if (HAL_LTDC_ConfigLayer(&hltdc, &pLayerCfg, 0) != HAL_OK) {
		Error_Handler();
	}

}

static void MX_SPI5_Init(void) {

	/* SPI5 parameter configuration*/
	hspi5.Instance = SPI5;
	hspi5.Init.Mode = SPI_MODE_MASTER;
	hspi5.Init.Direction = SPI_DIRECTION_2LINES;
	hspi5.Init.DataSize = SPI_DATASIZE_8BIT;
	hspi5.Init.CLKPolarity = SPI_POLARITY_LOW;
	hspi5.Init.CLKPhase = SPI_PHASE_1EDGE;
	hspi5.Init.NSS = SPI_NSS_SOFT;
	hspi5.Init.BaudRatePrescaler = SPI_BAUDRATEPRESCALER_16;
	hspi5.Init.FirstBit = SPI_FIRSTBIT_MSB;
	hspi5.Init.TIMode = SPI_TIMODE_DISABLE;
	hspi5.Init.CRCCalculation = SPI_CRCCALCULATION_DISABLE;
	hspi5.Init.CRCPolynomial = 10;
	if (HAL_SPI_Init(&hspi5) != HAL_OK) {
		Error_Handler();
	}

}

static void MX_TIM1_Init(void) {

	TIM_ClockConfigTypeDef sClockSourceConfig = { 0 };
	TIM_MasterConfigTypeDef sMasterConfig = { 0 };

	htim1.Instance = TIM1;
	htim1.Init.Prescaler = 167;
	htim1.Init.CounterMode = TIM_COUNTERMODE_UP;
	htim1.Init.Period = 65535;
	htim1.Init.ClockDivision = TIM_CLOCKDIVISION_DIV1;
	htim1.Init.RepetitionCounter = 0;
	htim1.Init.AutoReloadPreload = TIM_AUTORELOAD_PRELOAD_DISABLE;
	if (HAL_TIM_Base_Init(&htim1) != HAL_OK) {
		Error_Handler();
	}
	sClockSourceConfig.ClockSource = TIM_CLOCKSOURCE_INTERNAL;
	if (HAL_TIM_ConfigClockSource(&htim1, &sClockSourceConfig) != HAL_OK) {
		Error_Handler();
	}
	sMasterConfig.MasterOutputTrigger = TIM_TRGO_RESET;
	sMasterConfig.MasterSlaveMode = TIM_MASTERSLAVEMODE_DISABLE;
	if (HAL_TIMEx_MasterConfigSynchronization(&htim1, &sMasterConfig)
			!= HAL_OK) {
		Error_Handler();
	}

}

static void MX_TIM10_Init(void) {

	htim10.Instance = TIM10;
	htim10.Init.Prescaler = 1680 - 1;
	htim10.Init.CounterMode = TIM_COUNTERMODE_UP;
	htim10.Init.Period = 10000;
	htim10.Init.ClockDivision = TIM_CLOCKDIVISION_DIV1;
	htim10.Init.AutoReloadPreload = TIM_AUTORELOAD_PRELOAD_ENABLE;
	if (HAL_TIM_Base_Init(&htim10) != HAL_OK) {
		Error_Handler();
	}

}

static void MX_UART5_Init(void) {

	huart5.Instance = UART5;
	huart5.Init.BaudRate = 115200;
	huart5.Init.WordLength = UART_WORDLENGTH_8B;
	huart5.Init.StopBits = UART_STOPBITS_1;
	huart5.Init.Parity = UART_PARITY_NONE;
	huart5.Init.Mode = UART_MODE_TX_RX;
	huart5.Init.HwFlowCtl = UART_HWCONTROL_NONE;
	huart5.Init.OverSampling = UART_OVERSAMPLING_16;
	if (HAL_UART_Init(&huart5) != HAL_OK) {
		Error_Handler();
	}

}

static void MX_USART1_UART_Init(void) {

	huart1.Instance = USART1;
	huart1.Init.BaudRate = 115200;
	huart1.Init.WordLength = UART_WORDLENGTH_8B;
	huart1.Init.StopBits = UART_STOPBITS_1;
	huart1.Init.Parity = UART_PARITY_NONE;
	huart1.Init.Mode = UART_MODE_TX_RX;
	huart1.Init.HwFlowCtl = UART_HWCONTROL_NONE;
	huart1.Init.OverSampling = UART_OVERSAMPLING_16;
	if (HAL_UART_Init(&huart1) != HAL_OK) {
		Error_Handler();
	}

}

/* FMC initialization function */
static void MX_FMC_Init(void) {

	FMC_SDRAM_TimingTypeDef SdramTiming = { 0 };

	/** Perform the SDRAM1 memory initialization sequence
	 */
	hsdram1.Instance = FMC_SDRAM_DEVICE;
	/* hsdram1.Init */
	hsdram1.Init.SDBank = FMC_SDRAM_BANK2;
	hsdram1.Init.ColumnBitsNumber = FMC_SDRAM_COLUMN_BITS_NUM_8;
	hsdram1.Init.RowBitsNumber = FMC_SDRAM_ROW_BITS_NUM_12;
	hsdram1.Init.MemoryDataWidth = FMC_SDRAM_MEM_BUS_WIDTH_16;
	hsdram1.Init.InternalBankNumber = FMC_SDRAM_INTERN_BANKS_NUM_4;
	hsdram1.Init.CASLatency = FMC_SDRAM_CAS_LATENCY_3;
	hsdram1.Init.WriteProtection = FMC_SDRAM_WRITE_PROTECTION_DISABLE;
	hsdram1.Init.SDClockPeriod = FMC_SDRAM_CLOCK_PERIOD_2;
	hsdram1.Init.ReadBurst = FMC_SDRAM_RBURST_DISABLE;
	hsdram1.Init.ReadPipeDelay = FMC_SDRAM_RPIPE_DELAY_1;
	/* SdramTiming */
	SdramTiming.LoadToActiveDelay = 2;
	SdramTiming.ExitSelfRefreshDelay = 7;
	SdramTiming.SelfRefreshTime = 4;
	SdramTiming.RowCycleDelay = 7;
	SdramTiming.WriteRecoveryTime = 3;
	SdramTiming.RPDelay = 2;
	SdramTiming.RCDDelay = 2;

	if (HAL_SDRAM_Init(&hsdram1, &SdramTiming) != HAL_OK) {
		Error_Handler();
	}

}

static void MX_GPIO_Init(void) {
	GPIO_InitTypeDef GPIO_InitStruct = { 0 };

	/* GPIO Ports Clock Enable */
	__HAL_RCC_GPIOC_CLK_ENABLE();
	__HAL_RCC_GPIOF_CLK_ENABLE();
	__HAL_RCC_GPIOH_CLK_ENABLE();
	__HAL_RCC_GPIOA_CLK_ENABLE();
	__HAL_RCC_GPIOB_CLK_ENABLE();
	__HAL_RCC_GPIOG_CLK_ENABLE();
	__HAL_RCC_GPIOE_CLK_ENABLE();
	__HAL_RCC_GPIOD_CLK_ENABLE();

	/*Configure GPIO pin Output Level */
	HAL_GPIO_WritePin(GPIOC, NCS_MEMS_SPI_Pin | CSX_Pin | OTG_FS_PSO_Pin,
			GPIO_PIN_RESET);

	/*Configure GPIO pin Output Level */
	HAL_GPIO_WritePin(ACP_RST_GPIO_Port, ACP_RST_Pin, GPIO_PIN_RESET);

	/*Configure GPIO pin Output Level */
	HAL_GPIO_WritePin(GPIOD, RDX_Pin | WRX_DCX_Pin, GPIO_PIN_RESET);

	/*Configure GPIO pin Output Level */
	HAL_GPIO_WritePin(GPIOG, LD3_Pin | LD4_Pin, GPIO_PIN_RESET);

	/*Configure GPIO pins : NCS_MEMS_SPI_Pin CSX_Pin OTG_FS_PSO_Pin */
	GPIO_InitStruct.Pin = NCS_MEMS_SPI_Pin | CSX_Pin | OTG_FS_PSO_Pin;
	GPIO_InitStruct.Mode = GPIO_MODE_OUTPUT_PP;
	GPIO_InitStruct.Pull = GPIO_NOPULL;
	GPIO_InitStruct.Speed = GPIO_SPEED_FREQ_LOW;
	HAL_GPIO_Init(GPIOC, &GPIO_InitStruct);

	/*Configure GPIO pins : B1_Pin MEMS_INT1_Pin MEMS_INT2_Pin TP_INT1_Pin */
	GPIO_InitStruct.Pin = B1_Pin | MEMS_INT1_Pin | MEMS_INT2_Pin | TP_INT1_Pin;
	GPIO_InitStruct.Mode = GPIO_MODE_EVT_RISING;
	GPIO_InitStruct.Pull = GPIO_NOPULL;
	HAL_GPIO_Init(GPIOA, &GPIO_InitStruct);

	/*Configure GPIO pin : ACP_RST_Pin */
	GPIO_InitStruct.Pin = ACP_RST_Pin;
	GPIO_InitStruct.Mode = GPIO_MODE_OUTPUT_PP;
	GPIO_InitStruct.Pull = GPIO_NOPULL;
	GPIO_InitStruct.Speed = GPIO_SPEED_FREQ_LOW;
	HAL_GPIO_Init(ACP_RST_GPIO_Port, &GPIO_InitStruct);

	/*Configure GPIO pin : OTG_FS_OC_Pin */
	GPIO_InitStruct.Pin = OTG_FS_OC_Pin;
	GPIO_InitStruct.Mode = GPIO_MODE_EVT_RISING;
	GPIO_InitStruct.Pull = GPIO_NOPULL;
	HAL_GPIO_Init(OTG_FS_OC_GPIO_Port, &GPIO_InitStruct);

	/*Configure GPIO pin : BOOT1_Pin */
	GPIO_InitStruct.Pin = BOOT1_Pin;
	GPIO_InitStruct.Mode = GPIO_MODE_INPUT;
	GPIO_InitStruct.Pull = GPIO_NOPULL;
	HAL_GPIO_Init(BOOT1_GPIO_Port, &GPIO_InitStruct);

	/*Configure GPIO pin : TE_Pin */
	GPIO_InitStruct.Pin = TE_Pin;
	GPIO_InitStruct.Mode = GPIO_MODE_INPUT;
	GPIO_InitStruct.Pull = GPIO_NOPULL;
	HAL_GPIO_Init(TE_GPIO_Port, &GPIO_InitStruct);

	/*Configure GPIO pins : RDX_Pin WRX_DCX_Pin */
	GPIO_InitStruct.Pin = RDX_Pin | WRX_DCX_Pin;
	GPIO_InitStruct.Mode = GPIO_MODE_OUTPUT_PP;
	GPIO_InitStruct.Pull = GPIO_NOPULL;
	GPIO_InitStruct.Speed = GPIO_SPEED_FREQ_LOW;
	HAL_GPIO_Init(GPIOD, &GPIO_InitStruct);

	/*Configure GPIO pin : PD5 */
	GPIO_InitStruct.Pin = GPIO_PIN_5;
	GPIO_InitStruct.Mode = GPIO_MODE_AF_PP;
	GPIO_InitStruct.Pull = GPIO_NOPULL;
	GPIO_InitStruct.Speed = GPIO_SPEED_FREQ_VERY_HIGH;
	GPIO_InitStruct.Alternate = GPIO_AF7_USART2;
	HAL_GPIO_Init(GPIOD, &GPIO_InitStruct);

	/*Configure GPIO pins : LD3_Pin LD4_Pin */
	GPIO_InitStruct.Pin = LD3_Pin | LD4_Pin;
	GPIO_InitStruct.Mode = GPIO_MODE_OUTPUT_PP;
	GPIO_InitStruct.Pull = GPIO_NOPULL;
	GPIO_InitStruct.Speed = GPIO_SPEED_FREQ_LOW;
	HAL_GPIO_Init(GPIOG, &GPIO_InitStruct);

}

/* USER CODE BEGIN 4 */

/******************* DORJEE'S FUNCTIONS ***************/

//debugging print of qr scanned data
void output_protocol(char line[MAX_LINES][MAX_LINE_LENGTH], int lines) {
	for (int i = 0; i < lines; i++) {
		printf("%s\n", line[i]);
	}
}
int _write(int file, char *ptr, int len) {
	HAL_UART_Transmit(&huart1, (uint8_t*) ptr, len, HAL_MAX_DELAY);
	return len;
}

/******************** Flash Memory ********************/

/**
 * @brief: Erase the memory from an entire sector
 * @param Sector: The sector number
 * @retval: none
 */
void erase_sector(uint32_t Sector) {
	HAL_FLASH_Unlock();  // Unlock flash to enable erasing
	FLASH_Erase_Sector(sector_mapping(Sector), VOLTAGE_RANGE_3);
	HAL_FLASH_Lock();  // Lock flash after erasing
}

/**
 * @brief: Write a string to flash memory
 * @param data: string to be stored in flash memory
 * @param flash_address: address of string in flash memory that will be stored
 * @retval: none
 * Note: PLEASE UNLOCK AND LOCK FLASH BEFORE AND AFTER USING THIS FUNCTION,
 * IT DOES NOT DO IT ITSELF
 */
void write_to_flash(const char *data, uint32_t flash_address) {
	//HAL_FLASH_Unlock();  // Unlock flash for writing

	for (uint8_t i = 0; i < strlen(data); i++) {
		//printf("%c", data[i]);
		HAL_FLASH_Program(FLASH_TYPEPROGRAM_BYTE, flash_address + i, data[i]); // Write to flash
	}

	//HAL_FLASH_Lock();  // Lock flash after writing
}

/**
 * @brief: Read a string from flash memory. If failure, don't read
 * @param output: store the string in an output to be used
 * @param flash_address: address of string in flash memory that will be read
 * @retval: failure if its reading trash from flash memory.
 * it literally does not read from flash btw if it detects 0xFF at the start
 * that means your output buffer will not be updated
 */
uint8_t read_from_flash(char *output, uint32_t flash_address) {
	// Read byte by byte from flash memory, get a whole string in output variable
	for (uint8_t i = 0; i < MAX_LINE_LENGTH; i++) {
		char key = *(char*) (flash_address + i);
		//check if reading trash (0xFF) from flash memory
		if (key == 0xFF) {
			if (i == 0) {
				return 0;
			}
		} else {
			output[i] = key;
		}
	}
	output[strlen(output)] = '\0'; //add null to the end of string for printing
	//printf("output is %s and strlen: %d\n", output, strlen(output));

	//error handling. G-codes are less than 32 chars, anything more is trash
	if (strlen(output) < MAX_LINE_LENGTH) {
		return 1;
	} else {
		return 0;
	}

}

/**
 * @brief: Store array of G-code commands (protocol) into flash memory
 * @param num: number of G-code commands to store
 * @param gcode_file: array of G-code commands
 * @param sector: which sector to store protocol in
 * @retval: failure if sector is "full"
 */
uint8_t storeProtocol(char new_protocol[MAX_LINES][MAX_LINE_LENGTH],
		uint32_t sector) {

	//initialize variables
	int i = 0;  //protocol index
	int j = 0;  //line index
	char protocolStorage[MAX_PROTOCOLS_IN_SECTOR][MAX_LINES][MAX_LINE_LENGTH] =
			{ { { '\0' } } };
	uint32_t flash_address = get_sector_address(sector);

	//check if all sectors are full before storing a protocol
	uint8_t num_protocols = get_num_protocols_in_sector(sector);
	if (num_protocols == MAX_PROTOCOLS_IN_SECTOR) {
		return 0;
	}

	//read existing protocols in sector and put into the temp protocol storage
	for (i = 0; i < num_protocols; i++) {
		for (j = 0; j < MAX_LINES; j++) {
			//get the address for the current line in the current protocol
			uint32_t temp_address = flash_address + i * PROTOCOL_SIZE
					+ j * MAX_LINE_LENGTH;
			//read lines from memory into buffer until you reach garbage
			read_from_flash(protocolStorage[i][j], temp_address); //only updates protocolStorage if its a valid line from memory
		}
	}
	//output: we now have the existing protocols in the buffer.
	//they only have their first number of lines in. the rest of lines are null

	//put the new protocol into the temp protocol storage
	for (j = 0; j < MAX_LINES; j++) {
		//copy each line into the buffer from new protocol, should be null terminated from qr scanner
		if (new_protocol[j][0] != '\0') {
			strcpy(protocolStorage[i][j], new_protocol[j]);
		}
	}
	//we now have the new protocol in the buffer.
	//it only has the first number of lines in. the rest of lines are null

	output_protocol(protocolStorage[0], 10);
	output_protocol(protocolStorage[1], 10);

	//write existing protocols and new protocol to flash memory, string-by-string
	erase_sector(sector); //erase sector before writing
	HAL_FLASH_Unlock(); // Unlock flash for writing. note: the erase_sector() unlocks and locks itself
	for (i = 0; i < (num_protocols + 1); i++) {
		for (j = 0; j < MAX_LINES; j++) {
			uint32_t temp_address = flash_address + i * PROTOCOL_SIZE
					+ j * MAX_LINE_LENGTH;
			//write all strings that dont start with null to flash memory
			if (protocolStorage[i][j][0] != NULL) {
				write_to_flash(protocolStorage[i][j], temp_address);
			}

//			//if first character of a line is null from qr scanner or trash from flash, ignore it
//			if ((new_protocol[j][0] != '\0') && (new_protocol[j][0] != 0xFF)) {
//				uint32_t temp_address = flash_address + i * PROTOCOL_SIZE
//						+ j * MAX_LINE_LENGTH;
//				//printf("len: %d and data: %s", strlen(protocolStorage[i][j]), protocolStorage[i][j]);
//				write_to_flash(protocolStorage[i][j], temp_address);
//			}
		}
	}
	HAL_FLASH_Lock();  // Unlock flash for writing

	//output:flash memory now has the lines of protocol storage in there
	//the remaining space is still 0xFF in flash
	return 1;
}

//return number of protocols in the sector
//NOTE: it doesnt actually do that. it checks the top of the sector first
//if there is no protocol there. it will just assume the rest is empty.
uint8_t get_num_protocols_in_sector(uint32_t sector) {
	uint32_t flash_address = get_sector_address(sector);

	uint8_t i = 0;
	for (i = 0; i < MAX_PROTOCOLS_IN_SECTOR; i++) {
		uint8_t first_char = *(uint8_t*) (flash_address + i * PROTOCOL_SIZE);
		//memory in flash is default 0xFF
		if (first_char == 0xFF) {
			return i;
		}
	}
	return i;
}

//check each sector sequentially for any space.
//return the first sector number you find that has space
uint8_t getFreeSector(void) {
	uint8_t i = 1;
	//check every sector starting at 1
	for (i = 1; i < (NUMBER_OF_SECTORS + 1); i++) {
		//check each potential protocol slot in the current sector
		for (uint8_t j = 0; j < MAX_PROTOCOLS_IN_SECTOR; j++) {
			//check first char of the given protocol in the current sector
			uint32_t flash_address = get_sector_address(i) + j * PROTOCOL_SIZE;
			char first_char = *(char*) (flash_address);
			//if memory address is empty, this sector is free
			if (first_char == 0xFF) {
				return i;
			}
		}
	}
	//if somehow all sectors are full, return 15 or higher (16 in this case)
	return i + 1;
}

/**
 * @brief: Transmit protocol from flash memory to ESP32 via UART string-by-string
 * @param sector: which sector the protocol is stored in
 */
void transmitProtocol(uint32_t sector, uint32_t offset) {
	char output[MAX_LINE_LENGTH] = { '\0' };
	uint32_t flash_address = get_sector_address(sector) + offset * PROTOCOL_SIZE;

	//printf("\nNew Protocol\n"); //just for debugging

	//we need to process up to 1028 G-code commands
	//but if we run into an invalid string, gcode file is over
	for (uint8_t i = 0; i < MAX_LINES; i++) {
		//an alternative to resetting the temp buffer is to only read up to newline
		memset(output, 0, MAX_LINE_LENGTH); // Sets all elements of buffer to 0
		if (read_from_flash(output, flash_address + i * MAX_LINE_LENGTH)) {
			//printf("%s", output);
			HAL_UART_Transmit(&huart1, (uint8_t*) output, strlen(output),
			HAL_MAX_DELAY);
			HAL_UART_Transmit(&huart5, (uint8_t*) output, strlen(output),
			HAL_MAX_DELAY);
		}
	}
}

/**
 * @brief: Queue protocol from flash memory to RAM buffer
 * @param sector: which sector the protocol is stored in
 */
void queueProtocol(uint32_t sector, uint32_t offset) {
	char output[MAX_LINE_LENGTH] = { '\0' };
	uint32_t flash_address = get_sector_address(sector) + offset * PROTOCOL_SIZE;

	for (uint8_t i = 0; i < MAX_LINES; i++) {
		memset(output, 0, MAX_LINE_LENGTH); // Sets all elements of buffer to 0
		if (read_from_flash(output, flash_address + i * MAX_LINE_LENGTH)) {
			strcpy(queueBuffer[queueSize][i], output);
		}
	}
}

/**
 * @brief: Transmit queued protocols from RAM buffer to ESP32 via UART string-by-string
 * @param queueSize:
 */
void transmitQueuedProtocols(uint8_t queueSize) {
	for (uint8_t i = 0; i < queueSize; i++) {
		for (uint8_t j = 0; j < MAX_LINES; j++) {
			HAL_UART_Transmit(&huart1, (uint8_t*) queueBuffer[i][j],
					strlen(queueBuffer[i][j]), HAL_MAX_DELAY);
		}
	}
}

/**
 * @brief: Delete protocol from flash memory to ESP32 via UART string-by-string
 * @param sector: which sector the protocol is stored in
 * @param offset: the exact slot in the sector the protocol is stored in
 * @retval: none
 */
void deleteProtocol(uint32_t sector, uint32_t offset) {
	//initialize variables
	uint8_t new_offset = offset + 1; //have it range from 1-3
	int i = 0;
	int j = 0; //indices for moving through flash memory
	char protocolStorage[MAX_PROTOCOLS_IN_SECTOR][MAX_LINES][MAX_LINE_LENGTH] =
			{ { { '\0' } } };
	uint32_t flash_address = get_sector_address(sector);
	char trashLine[MAX_LINE_LENGTH];
	memset(trashLine, 0xFF, sizeof(trashLine));
	char nullLine[MAX_LINE_LENGTH];
	memset(nullLine, 0x00, sizeof(nullLine));
	uint8_t num_protocols = get_num_protocols_in_sector(sector);

	int a = 0;
	int b = 0; //separate indices for protocolstorage

	//copy all protocols in sector to local buffer
	for (i = 0; i < MAX_PROTOCOLS_IN_SECTOR; i++) {
		if (i != offset) {
			//copy all lines of the protocol into the buffer
			for (j = 0; j < MAX_LINES; j++) {
				//get the address for the current line in the current protocol
				uint32_t temp_address = flash_address + i * PROTOCOL_SIZE
						+ j * MAX_LINE_LENGTH;
				//read lines from memory into buffer until you reach garbage
				read_from_flash(protocolStorage[a][b], temp_address); //only updates protocolStorage if its a valid line from memory
				b++;
			}
			a++;
			b = 0;
		}
	}

	//write existing protocols except the one to be deleted back to flash
	erase_sector(sector); //erase sector before writing
	HAL_FLASH_Unlock(); // Unlock flash for writing. note: the erase_sector() unlocks and locks itself
	for (i = 0; i < MAX_PROTOCOLS_IN_SECTOR; i++) {
		for (j = 0; j < MAX_LINES; j++) {
			//if first character of a line is null from qr scanner or trash from flash, ignore it
			uint32_t temp_address = flash_address + i * PROTOCOL_SIZE
					+ j * MAX_LINE_LENGTH;
			write_to_flash(protocolStorage[i][j], temp_address);

		}
	}
	HAL_FLASH_Lock();  // Unlock flash for writing
}

// Function to write a uint32_t number to flash memory
void write_number_to_flash(uint32_t flash_address, uint32_t number) {
	HAL_FLASH_Program(FLASH_TYPEPROGRAM_WORD, flash_address, number);
}

/******************** Touchscreen *********************/

void Touch_Init(void) {
	if (BSP_TS_Init(240, 320) != TS_OK) {
		BSP_LCD_DisplayStringAt(0, 10, (uint8_t*) "Failure", CENTER_MODE);
		printf("Touchscreen Initialization failure\n");
	} else {
		BSP_LCD_DisplayStringAt(0, 300, (uint8_t*) "Success", CENTER_MODE);
		printf("Touchscreen Initialization success\n");
	}
}
/**
 * @brief: Draw main page and handle button label and status updates
 * @param: page_num: determines which page should be drawn from 1-10
 * @retval: none
 */
void DrawMainPage(uint8_t page_num) {
	//Draw "Protocol Title" box
	BSP_LCD_Clear(LCD_COLOR_WHITE);
	char empty[20] = "Empty\n"; //strings from flash memory come with newline at end
	char pageTitle[20] = "";
	sprintf(pageTitle, "Page %d", page_num);
	BSP_LCD_SetTextColor(LCD_COLOR_BLACK);
	BSP_LCD_SetFont(&Font20);
	BSP_LCD_SetBackColor(LCD_COLOR_RED);
	BSP_LCD_DisplayStringAt(10, 10, (uint8_t*) pageTitle, CENTER_MODE);

	//get button label info from flash memory
	char readBuffer1[MAX_LINE_LENGTH] = ""; //initialize with nulls
	char readBuffer2[MAX_LINE_LENGTH] = ""; //initialize with nulls
	char readBuffer3[MAX_LINE_LENGTH] = ""; //initialize with nulls

	//if the protocol exists, read from it. else, name it empty
	if (read_from_flash(readBuffer1, get_sector_address(page_num))) {
		strcpy(buttons[0].label, readBuffer1);
		buttons[0].status = NOT_EMPTY;
	} else {
		strcpy(buttons[0].label, empty);
		buttons[0].status = EMPTY;
	}
	if (read_from_flash(readBuffer2,
			get_sector_address(page_num) + PROTOCOL_SIZE)) {
		strcpy(buttons[1].label, readBuffer2);
		buttons[1].status = NOT_EMPTY;
	} else {
		strcpy(buttons[1].label, empty);
		buttons[1].status = EMPTY;
	}
	if (read_from_flash(readBuffer3,
			get_sector_address(page_num) + 2 * PROTOCOL_SIZE)) {
		strcpy(buttons[2].label, readBuffer3);
		buttons[2].status = NOT_EMPTY;
	} else {
		strcpy(buttons[2].label, empty);
		buttons[2].status = EMPTY;
	}

	// Draw buttons
	BSP_LCD_SetTextColor(LCD_COLOR_BLUE);
	for (int i = 0; i < NUM_BUTTONS; i++) {
		BSP_LCD_FillRect(buttons[i].x, buttons[i].y, buttons[i].w,
				buttons[i].h);
		BSP_LCD_SetTextColor(LCD_COLOR_WHITE);
		BSP_LCD_SetBackColor(LCD_COLOR_BLUE);
		if (buttons[i].label[10] == NEWLINE_CHAR) {
		}
		buttons[i].label[strlen(buttons[i].label) - 1] = ' '; //dont display null terminator
		BSP_LCD_DisplayStringAt(buttons[i].x + 10, buttons[i].y + 10,
				(uint8_t*) buttons[i].label, LEFT_MODE);
		BSP_LCD_SetTextColor(LCD_COLOR_BLUE);
	}

	// Draw "Next" button
	if (page_num != 10) {
		BSP_LCD_SetTextColor(LCD_COLOR_RED);
		BSP_LCD_FillRect(nextButton.x, nextButton.y, nextButton.w,
				nextButton.h);
		BSP_LCD_SetTextColor(LCD_COLOR_WHITE);
		BSP_LCD_SetBackColor(LCD_COLOR_RED);
		BSP_LCD_DisplayStringAt(nextButton.x + 10, nextButton.y + 10,
				(uint8_t*) nextButton.label, LEFT_MODE);
	}

	// Draw "Back" button
	if (page_num != 1) {
		BSP_LCD_SetTextColor(LCD_COLOR_RED);
		BSP_LCD_FillRect(backButton.x, backButton.y, backButton.w,
				backButton.h);
		BSP_LCD_SetTextColor(LCD_COLOR_WHITE);
		BSP_LCD_SetBackColor(LCD_COLOR_RED);
		BSP_LCD_DisplayStringAt(backButton.x + 10, backButton.y + 10,
				(uint8_t*) backButton.label, LEFT_MODE);
	}

	//draw "Queue" button on page 1
	if (page_num == 1) {
		BSP_LCD_SetTextColor(LCD_COLOR_YELLOW);
		BSP_LCD_FillRect(queueButton.x, queueButton.y, queueButton.w,
				queueButton.h);
		BSP_LCD_SetTextColor(LCD_COLOR_BLACK);
		BSP_LCD_SetBackColor(LCD_COLOR_YELLOW);
		BSP_LCD_DisplayStringAt(queueButton.x + 10, queueButton.y + 10,
				(uint8_t*) queueButton.label, LEFT_MODE);
	}
}

void DrawInfoPage(char protocolTitle[MAX_LINE_LENGTH]) {
	BSP_LCD_Clear(LCD_COLOR_WHITE);
	//Display protocol name at top of screen
	BSP_LCD_SetTextColor(LCD_COLOR_BLACK);
	BSP_LCD_SetBackColor(LCD_COLOR_RED);
	BSP_LCD_DisplayStringAt(10, 10, (uint8_t*) protocolTitle, CENTER_MODE);

	//Draw "QueueSelect" button on select page
	BSP_LCD_SetTextColor(LCD_COLOR_BLUE);
	BSP_LCD_FillRect(queueSelectButton.x, queueSelectButton.y,
			queueSelectButton.w, queueSelectButton.h);
	BSP_LCD_SetTextColor(LCD_COLOR_WHITE);
	BSP_LCD_SetBackColor(LCD_COLOR_BLUE);
	BSP_LCD_DisplayStringAt(queueSelectButton.x + 10, queueSelectButton.y + 10,
			(uint8_t*) queueSelectButton.label, LEFT_MODE);

	//Draw "Select" button
	BSP_LCD_SetTextColor(LCD_COLOR_BLUE);
	BSP_LCD_FillRect(selectButton.x, selectButton.y, selectButton.w,
			selectButton.h);
	BSP_LCD_SetTextColor(LCD_COLOR_WHITE);
	BSP_LCD_SetBackColor(LCD_COLOR_BLUE);
	BSP_LCD_DisplayStringAt(selectButton.x + 10, selectButton.y + 10,
			(uint8_t*) selectButton.label, LEFT_MODE);

	//Draw "Delete" button
	BSP_LCD_SetTextColor(LCD_COLOR_BLUE);
	BSP_LCD_FillRect(deleteButton.x, deleteButton.y, deleteButton.w,
			deleteButton.h);
	BSP_LCD_SetTextColor(LCD_COLOR_WHITE);
	BSP_LCD_SetBackColor(LCD_COLOR_BLUE);
	BSP_LCD_DisplayStringAt(deleteButton.x + 10, deleteButton.y + 10,
			(uint8_t*) deleteButton.label, LEFT_MODE);

	// Draw "Back" button
	BSP_LCD_SetTextColor(LCD_COLOR_RED);
	BSP_LCD_FillRect(backButton.x, backButton.y, backButton.w, backButton.h);
	BSP_LCD_SetTextColor(LCD_COLOR_WHITE);
	BSP_LCD_SetBackColor(LCD_COLOR_RED);
	BSP_LCD_DisplayStringAt(backButton.x + 10, backButton.y + 10,
			(uint8_t*) backButton.label, LEFT_MODE);
}

void DrawQueuePage(uint8_t queueSize) {
	BSP_LCD_Clear(LCD_COLOR_WHITE);
	char pageTitle[20] = "";
	sprintf(pageTitle, "Queue Size: %d", queueSize);
	//Display Queue at top of the screen
	BSP_LCD_SetFont(&Font20);
	BSP_LCD_SetTextColor(LCD_COLOR_BLACK);
	BSP_LCD_SetBackColor(LCD_COLOR_RED);
	BSP_LCD_DisplayStringAt(10, 10, (uint8_t*) pageTitle, CENTER_MODE);

	//display protocols in queue here
	BSP_LCD_SetFont(&Font16);
	BSP_LCD_SetTextColor(LCD_COLOR_BLACK);
	BSP_LCD_SetBackColor(LCD_COLOR_WHITE);
	char format[20] = "";
	for (uint8_t i = 0; i < queueSize; i++) {
		sprintf(format, "%d.) ", i + 1);
		BSP_LCD_DisplayStringAt(10, 50 + i * 20, (uint8_t*) format, LEFT_MODE);
		BSP_LCD_DisplayStringAt(60, 50 + i * 20, (uint8_t*) queueBuffer[i][0],
				LEFT_MODE);
	}
	BSP_LCD_SetFont(&Font20);

	//Draw "Run" button
	BSP_LCD_SetTextColor(LCD_COLOR_RED);
	BSP_LCD_FillRect(runButton.x, runButton.y, runButton.w, runButton.h);
	BSP_LCD_SetTextColor(LCD_COLOR_WHITE);
	BSP_LCD_SetBackColor(LCD_COLOR_RED);
	BSP_LCD_DisplayStringAt(runButton.x + 10, runButton.y + 10,
			(uint8_t*) runButton.label, LEFT_MODE);

	// Draw "Back" button
	BSP_LCD_SetTextColor(LCD_COLOR_RED);
	BSP_LCD_FillRect(backButton.x, backButton.y, backButton.w, backButton.h);
	BSP_LCD_SetTextColor(LCD_COLOR_WHITE);
	BSP_LCD_SetBackColor(LCD_COLOR_RED);
	BSP_LCD_DisplayStringAt(backButton.x + 10, backButton.y + 10,
			(uint8_t*) backButton.label, LEFT_MODE);
}

void DrawConfirmationPage(uint32_t sector, uint32_t offset) {
	BSP_LCD_Clear(LCD_COLOR_WHITE);

	//display confirmation text
	BSP_LCD_SetTextColor(LCD_COLOR_BLACK);
	BSP_LCD_SetBackColor(LCD_COLOR_WHITE);
	BSP_LCD_DisplayStringAt(10, 10, (uint8_t*) "Confirm Delete:", LEFT_MODE);

	//Display protocol name for deletion
	BSP_LCD_SetTextColor(LCD_COLOR_BLACK);
	BSP_LCD_SetBackColor(LCD_COLOR_WHITE);
	BSP_LCD_DisplayStringAt(10, 30, (uint8_t*) buttons[offset].label,
			CENTER_MODE);

	//Draw "Confirm" button
	BSP_LCD_SetTextColor(LCD_COLOR_BLUE);
	BSP_LCD_FillRect(confirmButton.x, confirmButton.y, confirmButton.w,
			confirmButton.h);
	BSP_LCD_SetTextColor(LCD_COLOR_WHITE);
	BSP_LCD_SetBackColor(LCD_COLOR_BLUE);
	BSP_LCD_DisplayStringAt(confirmButton.x + 10, confirmButton.y + 10,
			(uint8_t*) confirmButton.label, LEFT_MODE);

	// Draw "Back" button
	BSP_LCD_SetTextColor(LCD_COLOR_RED);
	BSP_LCD_FillRect(backButton.x, backButton.y, backButton.w, backButton.h);
	BSP_LCD_SetTextColor(LCD_COLOR_WHITE);
	BSP_LCD_SetBackColor(LCD_COLOR_RED);
	BSP_LCD_DisplayStringAt(backButton.x + 10, backButton.y + 10,
			(uint8_t*) backButton.label, LEFT_MODE);
}

void DrawPageFinish() {
	BSP_LCD_Clear(LCD_COLOR_WHITE);

	//Draw "Success!" box
	BSP_LCD_SetTextColor(LCD_COLOR_BLACK);
	BSP_LCD_SetBackColor(LCD_COLOR_RED);
	BSP_LCD_DisplayStringAt(selectButton.x + 10, selectButton.y + 10,
			(uint8_t*) "Success!", LEFT_MODE);

	// Draw "Back" button
	BSP_LCD_SetTextColor(LCD_COLOR_RED);
	BSP_LCD_FillRect(backButton.x, backButton.y, backButton.w, backButton.h);
	BSP_LCD_SetTextColor(LCD_COLOR_WHITE);
	BSP_LCD_SetBackColor(LCD_COLOR_RED);
	BSP_LCD_DisplayStringAt(backButton.x + 10, backButton.y + 10,
			(uint8_t*) "Done", LEFT_MODE);
}

//fix this function and give it a description
uint8_t HandleTouch(void) {
	//store the coordinates of the user touch in "TS_State"
	BSP_TS_GetState(&TS_State);
	//do nothing if no touch detect
	if (!TS_State.TouchDetected) {
		return 0;
	}

	//init variables if a touch is detected
	char Empty_str[20] = "Empty\n"; //strings from flash memory come with newline at end
	static uint8_t protocol_num;
	static uint8_t protocol_offset = 0;
	//the y value has issues of being flipped and also needing to click below button
	TS_State.Y = (BSP_LCD_GetYSize() - TS_State.Y) - Y_OFFSET;

	//start state machine for touch handling
	switch (currentPage) {
	case PAGE_MAIN:
		//back button
		if (TS_State.X >= backButton.x
				&& TS_State.X <= (backButton.x + backButton.w)
				&& TS_State.Y >= backButton.y
				&& TS_State.Y <= (backButton.y + backButton.h)
				&& (pageNum != 1)) {
			pageNum--;
			DrawMainPage(pageNum);
			if (pageNum == 1) {
				//next page wont register touch until you let go
				while (TS_State.TouchDetected) {
					BSP_TS_GetState(&TS_State);
					if (!TS_State.TouchDetected) {
					}
					HAL_Delay(20); //WOOOO CANT TOUCH UNLESS YOU RELASE. the clk speed is super fast, need delay. ok if you slide the pen it breaks, but that dont count
				}
			}
			HAL_Delay(SCREEN_DELAY);
		}
		//next button
		if (TS_State.X >= nextButton.x
				&& TS_State.X <= (nextButton.x + nextButton.w)
				&& TS_State.Y >= nextButton.y
				&& TS_State.Y <= (nextButton.y + nextButton.h)
				&& (pageNum != 10)) {
			pageNum++;
			DrawMainPage(pageNum);
			HAL_Delay(SCREEN_DELAY);
		}
		//queue button
		if (TS_State.X >= queueButton.x
				&& TS_State.X <= (queueButton.x + queueButton.w)
				&& TS_State.Y >= queueButton.y
				&& TS_State.Y <= (queueButton.y + queueButton.h)
				&& (pageNum == 1)) {
			DrawQueuePage(queueSize);
			currentPage = PAGE_QUEUE;
			//next page wont register touch until you let go
			while (TS_State.TouchDetected) {
				BSP_TS_GetState(&TS_State);
				if (!TS_State.TouchDetected) {
				}
				HAL_Delay(20); //WOOOO CANT TOUCH UNLESS YOU RELASE. the clk speed is super fast, need delay. ok if you slide the pen it breaks, but that dont count
			}
			HAL_Delay(SCREEN_DELAY);
		}
		//3 protocol buttons
		for (int i = 0; i < NUM_BUTTONS; i++) {
			if (TS_State.X >= buttons[i].x
					&& TS_State.X <= (buttons[i].x + buttons[i].w)
					&& TS_State.Y >= buttons[i].y
					&& TS_State.Y <= (buttons[i].y + buttons[i].h)) {
				//check which button has been pressed
				if (i == 0) {
					protocol_num = 1;
					protocol_offset = 0;
				} else if (i == 1) {
					protocol_num = 1;
					protocol_offset = 1;
				} else if (i == 2) {
					protocol_num = 1;
					protocol_offset = 2;
				}
				//dont draw next page if the button says "Empty"
				if (buttons[i].status == NOT_EMPTY) {
					currentPage = PAGE_SELECT;
					DrawInfoPage(buttons[i].label);
				}
				//next page wont register touch until you let go
				while (TS_State.TouchDetected) {
					BSP_TS_GetState(&TS_State);
					if (!TS_State.TouchDetected) {
					}
					HAL_Delay(20); //WOOOO CANT TOUCH UNLESS YOU RELASE. the clk speed is super fast, need delay. ok if you slide the pen it breaks, but that dont count
				}
				return;
			}
		}
		break;
	case PAGE_SELECT:
		//back button
		if (TS_State.X >= backButton.x
				&& TS_State.X <= (backButton.x + backButton.w)
				&& TS_State.Y >= backButton.y
				&& TS_State.Y <= (backButton.y + backButton.h)) {
			currentPage = PAGE_MAIN;
			DrawMainPage(pageNum);
		}
		//queueSelect button
		if (TS_State.X >= queueSelectButton.x
				&& TS_State.X <= (queueSelectButton.x + queueSelectButton.w)
				&& TS_State.Y >= queueSelectButton.y
				&& TS_State.Y <= (queueSelectButton.y + queueSelectButton.h)) {
			HAL_Delay(20);
			//store the protocol in queueBuffer
			if (queueSize < MAX_QUEUE_SIZE) {
				queueProtocol(pageNum, protocol_offset);
				queueSize++;
				currentPage = PAGE_QUEUE;
				DrawQueuePage(queueSize);
			} else {
				//handle queue buffer being full
			}
		}
		//select button
		if (TS_State.X >= selectButton.x
				&& TS_State.X <= (selectButton.x + selectButton.w)
				&& TS_State.Y >= selectButton.y
				&& TS_State.Y <= (selectButton.y + selectButton.h)) {
			HAL_Delay(20);
			//transmit protocol and move to finish page
			transmitProtocol(pageNum, protocol_offset);
			currentPage = PAGE_FINISH;
			DrawPageFinish();
		}
		//delete button
		if (TS_State.X >= deleteButton.x
				&& TS_State.X <= (deleteButton.x + deleteButton.w)
				&& TS_State.Y >= deleteButton.y
				&& TS_State.Y <= (deleteButton.y + deleteButton.h)) {
			//move to delete confirmation page
			currentPage = PAGE_CONFIRMATION;
			DrawConfirmationPage(pageNum, protocol_offset);
		}
		//next page wont register touch until you let go
		while (TS_State.TouchDetected) {
			BSP_TS_GetState(&TS_State);
			if (!TS_State.TouchDetected) {
			}
			HAL_Delay(20); //WOOOO CANT TOUCH UNLESS YOU RELASE. the clk speed is super fast, need delay. ok if you slide the pen it breaks, but that dont count
		}
		break;
	case PAGE_QUEUE:
		//back button
		if (TS_State.X >= backButton.x
				&& TS_State.X <= (backButton.x + backButton.w)
				&& TS_State.Y >= backButton.y
				&& TS_State.Y <= (backButton.y + backButton.h)) {
			currentPage = PAGE_MAIN;
			DrawMainPage(pageNum);
			//next page wont register touch until you let go
			while (TS_State.TouchDetected) {
				BSP_TS_GetState(&TS_State);
				if (!TS_State.TouchDetected) {
				}
				HAL_Delay(20); //WOOOO CANT TOUCH UNLESS YOU RELASE. the clk speed is super fast, need delay. ok if you slide the pen it breaks, but that dont count
			}
		}
		//run button
		if (TS_State.X >= runButton.x
				&& TS_State.X <= (runButton.x + runButton.w)
				&& TS_State.Y >= runButton.y
				&& TS_State.Y <= (runButton.y + runButton.h)) {
			HAL_Delay(20);
			//handle queue functionality here dorjee
			transmitQueuedProtocols(queueSize);
			queueSize = 0;
			currentPage = PAGE_FINISH;
			DrawPageFinish();
		}
		break;
	case PAGE_CONFIRMATION:
		//back button
		if (TS_State.X >= backButton.x
				&& TS_State.X <= (backButton.x + backButton.w)
				&& TS_State.Y >= backButton.y
				&& TS_State.Y <= (backButton.y + backButton.h)) {
			currentPage = PAGE_SELECT;
			DrawInfoPage(buttons[i].label);
		}
		//confirm button
		if (TS_State.X >= confirmButton.x
				&& TS_State.X <= (confirmButton.x + confirmButton.w)
				&& TS_State.Y >= confirmButton.y
				&& TS_State.Y <= (confirmButton.y + confirmButton.h)) {
			HAL_Delay(20);
			//delete protocol and go back to main page
			deleteProtocol(pageNum, protocol_offset);
			currentPage = PAGE_MAIN;
			DrawMainPage(pageNum);
		}
		//next page wont register touch until you let go
		while (TS_State.TouchDetected) {
			BSP_TS_GetState(&TS_State);
			if (!TS_State.TouchDetected) {
			}
			HAL_Delay(20); //WOOOO CANT TOUCH UNLESS YOU RELASE. the clk speed is super fast, need delay. ok if you slide the pen it breaks, but that dont count
		}
		break;
	case PAGE_FINISH:
		if (TS_State.X >= backButton.x
				&& TS_State.X <= (backButton.x + backButton.w)
				&& TS_State.Y >= backButton.y
				&& TS_State.Y <= (backButton.y + backButton.h)) {
			currentPage = PAGE_MAIN;
			DrawMainPage(pageNum);
		}
		break;
	}
}

//I name sectors from 1-14. the actual sectors are from 5-23. this functions maps them
uint32_t get_sector_address(uint32_t sector) {
	switch (sector) {
	case 1:
		return SECTOR_5;
	case 2:
		return SECTOR_6;
	case 3:
		return SECTOR_7;
	case 4:
		return SECTOR_8;
	case 5:
		return SECTOR_9;
	case 6:
		return SECTOR_10;
	case 7:
		return SECTOR_11;
	case 8:
		return SECTOR_17;
	case 9:
		return SECTOR_18;
	case 10:
		return SECTOR_19;
	case 11:
		return SECTOR_20;
	case 12:
		return SECTOR_21;
	case 13:
		return SECTOR_22;
	case 14:
		return SECTOR_23;
	default:
		break;
	}
}

uint32_t sector_mapping(uint32_t sector) {
	switch (sector) {
	case 1:
		return 5;
	case 2:
		return 6;
	case 3:
		return 7;
	case 4:
		return 8;
	case 5:
		return 9;
	case 6:
		return 10;
	case 7:
		return 11;
	case 8:
		return 17;
	case 9:
		return 18;
	case 10:
		return 19;
	case 11:
		return 20;
	case 12:
		return 21;
	case 13:
		return 22;
	case 14:
		return 23;
	}
}

/* USER CODE END 4 */

void HAL_TIM_PeriodElapsedCallback(TIM_HandleTypeDef *htim) {
	if (htim->Instance == TIM6) {
		HAL_IncTick();
	}
	/* USER CODE BEGIN Callback 1 */

	//10 hz interrupt
	if (htim == &htim10) {
		if (!USB_BUSY) {
			checkTouchFlag = 1;
		}
		count++;
	}

	//use this for a slower frequency application
	if (count == 5) {
		//checkTouchFlag = 1;
		count = 0;
	}
	/* USER CODE END Callback 1 */
}

void Error_Handler(void) {
	__disable_irq();
	while (1) {
	}
}
